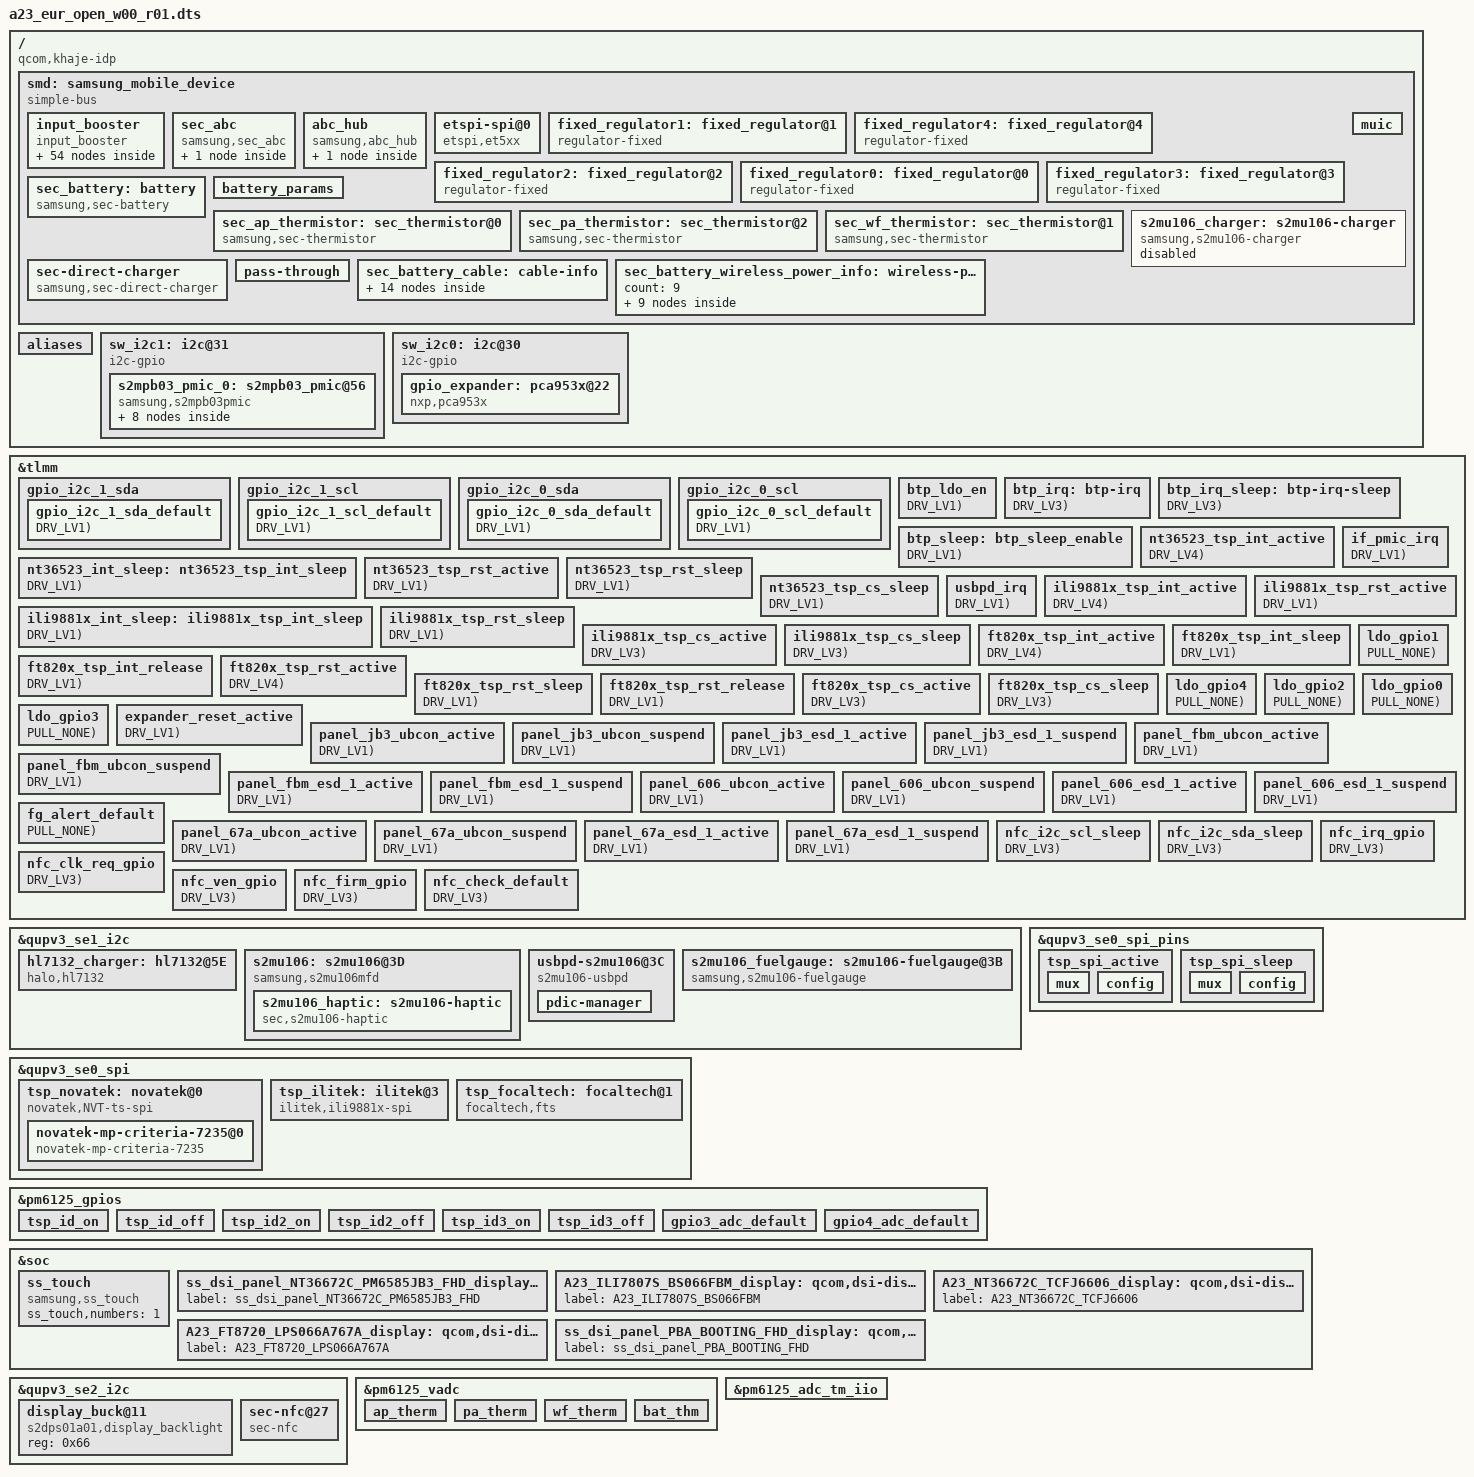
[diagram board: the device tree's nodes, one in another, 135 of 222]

/*
 * Copyright (c) 2018 Samsung Electronics Co., Ltd.
 *              http://www.samsung.com
 *
 * This program is free software; you can redistribute it and/or modify
 * it under the terms of the GNU General Public License version 2 as
 * published by the Free Software Foundation.
*/

/dts-v1/;
/plugin/;
/ {
	fragment@smd {
		target-path = "/";
		__overlay__ {
			smd: samsung_mobile_device {
				compatible = "simple-bus";
			};
		};
	};
};

/* #include "../../sec_pinctrl_wrapper.dtsi" */      /* From sec_pinctrl_wrapper.py */
#define PIN_AP_FUNC_INPUT		"gpio"
#define PIN_AP_FUNC_OUTPUT		"gpio"
#define PIN_AP_FUNC_OUTPUT_LOW		"gpio"
#define PIN_AP_FUNC_OUTPUT_HIGH		"gpio"
#define PIN_AP_FUNC_INPUT_WAKEUP	"gpio"
#define PIN_AP_FUNC_GCC_GP1		"gcc_gp1"
#define PIN_AP_FUNC_GCC_GP2		"gcc_gp2"
#define PIN_AP_FUNC_GCC_GP3		"gcc_gp3"
#define PIN_AP_FUNC_SIMPLE_GPIO		"gpio"
#define PIN_AP_FUNC_MDP_VSYNC		"mdp_vsync"
#define PIN_AP_FUNC_CAM_MCLK		"cam_mclk"

#define	PIN_AP_FUNC_QUP0	"qup0"
#define	PIN_AP_FUNC_QUP1	"qup1"
#define	PIN_AP_FUNC_QUP2	"qup2"
#define	PIN_AP_FUNC_QUP3	"qup3"
#define	PIN_AP_FUNC_QUP4	"qup4"
#define	PIN_AP_FUNC_QUP5	"qup5"
#define	PIN_AP_FUNC_QUP6	"qup6"
#define	PIN_AP_FUNC_QUP7	"qup7"
#define	PIN_AP_FUNC_QUP8	"qup8"
#define	PIN_AP_FUNC_QUP9	"qup9"
#define	PIN_AP_FUNC_QUP10	"qup10"
#define	PIN_AP_FUNC_QUP11	"qup11"
#define	PIN_AP_FUNC_QUP12	"qup12"
#define	PIN_AP_FUNC_QUP13	"qup13"
#define	PIN_AP_FUNC_QUP14	"qup14"
#define	PIN_AP_FUNC_QUP15	"qup15"
#define	PIN_AP_FUNC_QUP16	"qup16"
#define	PIN_AP_FUNC_QUP17	"qup17"
#define	PIN_AP_FUNC_QUP18	"qup18"
#define	PIN_AP_FUNC_QUP19	"qup19"

#define	PIN_AP_FUNC_QUP00	"qup00"
#define	PIN_AP_FUNC_QUP01	"qup01"
#define	PIN_AP_FUNC_QUP02	"qup02"
#define	PIN_AP_FUNC_QUP03	"qup03"
#define	PIN_AP_FUNC_QUP04	"qup04"

/* No support: Build error */
#define PIN_AP_FUNC_PWM		none

#define PIN_PM_FUNC_INPUT		"normal"
#define PIN_PM_FUNC_OUTPUT		"normal"
#define PIN_PM_FUNC_OUTPUT_HIGH		"normal"
#define PIN_PM_FUNC_OUTPUT_LOW		"normal"
#define PIN_PM_FUNC_INPUT_WAKEUP	"normal"
#define PIN_PM_FUNC_PWM			"func1"

#define PIN_DT_FUNC_INPUT		input-enable
#define PIN_DT_FUNC_INPUT_WAKEUP	input-enable
#define PIN_DT_FUNC_OUTPUT_HIGH		output-high
#define PIN_DT_FUNC_OUTPUT_LOW		output-low
#define PIN_DT_FUNC_GCC_GP1		output-high
#define PIN_DT_FUNC_SIMPLE_GPIO		/delete-property/ DUMMY
#define PIN_DT_FUNC_MDP_VSYNC		/delete-property/ DUMMY

#define PIN_DT_FUNC_QUP0	none
#define PIN_DT_FUNC_QUP1	none
#define PIN_DT_FUNC_QUP2	none
#define PIN_DT_FUNC_QUP3	none
#define PIN_DT_FUNC_QUP4	none
#define PIN_DT_FUNC_QUP5	none
#define PIN_DT_FUNC_QUP6	none
#define PIN_DT_FUNC_QUP7	none
#define PIN_DT_FUNC_QUP8	none
#define PIN_DT_FUNC_QUP9	none
#define PIN_DT_FUNC_QUP10	none
#define PIN_DT_FUNC_QUP11	none
#define PIN_DT_FUNC_QUP12	none
#define PIN_DT_FUNC_QUP13	none
#define PIN_DT_FUNC_QUP14	none
#define PIN_DT_FUNC_QUP15	none
#define PIN_DT_FUNC_QUP16	none
#define PIN_DT_FUNC_QUP17	none
#define PIN_DT_FUNC_QUP18	none
#define PIN_DT_FUNC_QUP19	none

#define PIN_DT_FUNC_QUP00	none
#define PIN_DT_FUNC_QUP01	none
#define PIN_DT_FUNC_QUP02	none
#define PIN_DT_FUNC_QUP03	none
#define PIN_DT_FUNC_QUP04	none

/* Only for PMIC */
#define PIN_DT_FUNC_PWM		drive-push-pull

#define PIN_PULL_NONE	bias-disable
#define PIN_PULL_DOWN	bias-pull-down
#define PIN_PULL_UP	bias-pull-up
#define PIN_PULL_OPEN	bias-high-impedance

/*
 * HDRV value | Typical GPIO
 *   (dec)    |       (mA)
 *     0      |       2
 *     1      |       4
 *     2      |       6
 *     3      |       8
 *     4      |       10
 *     5      |       12
 *     6      |       14
 *     7      |       16
 */

#define PIN_AP_DRV_LV1	2
#define PIN_AP_DRV_LV2	4
#define PIN_AP_DRV_LV3	6
#define PIN_AP_DRV_LV4	8
#define PIN_AP_DRV_LV5	10
#define PIN_AP_DRV_LV6	12
#define PIN_AP_DRV_LV7	14
#define PIN_AP_DRV_LV8	16

/*
 * QCOM PMIC GPIO : Need to check!!
 * NO	| 0
 * LOW	| 1	| 0.15mA @ 1.8V
 * MID	| 2	| 0.6mA @ 1.8V
 * HIGH	| 3	| 0.9mA @ 1.8V
 */

#define PIN_PM_DRV_LV1	0
#define PIN_PM_DRV_LV2	0
#define PIN_PM_DRV_LV3	1
#define PIN_PM_DRV_LV4	1
#define PIN_PM_DRV_LV5	2
#define PIN_PM_DRV_LV6	2
#define PIN_PM_DRV_LV7	3
#define PIN_PM_DRV_LV8	3

#define PIN_EXP_PULL_NONE	bias-disable
#define PIN_EXP_PULL_DOWN	bias-pull-down
#define PIN_EXP_PULL_UP		bias-pull-up

#define PIN_EXP_FUNC_INPUT		"normal"
#define PIN_EXP_FUNC_INPUT_WAKEUP	"normal"
#define PIN_EXP_FUNC_OUTPUT		"normal"
#define PIN_EXP_FUNC_OUTPUT_LOW		"normal"
#define PIN_EXP_FUNC_OUTPUT_HIGH	"normal"
#define PIN_EXP_FUNC_SIMPLE_GPIO	"normal"

#define PIN_EXP_DRV_LV1		0
#define PIN_EXP_DRV_LV2		0
#define PIN_EXP_DRV_LV3		1
#define PIN_EXP_DRV_LV4		1
#define PIN_EXP_DRV_LV5		2
#define PIN_EXP_DRV_LV6		2
#define PIN_EXP_DRV_LV7		3
#define PIN_EXP_DRV_LV8		3

#define PIN_EXPAND(pin) #pin

#define GPIO_KEY_WAKEUP		gpio-key,wakeup
#define GPIO_KEY_NONE		none
#define GPIO_KEY_CAN_DISABLE	linux,can-disable
#define GPIO_KEY_CANNOT_DISABLE	linux,cannot-disable

#define SEC_GPIO(src, type, num)	PIN_EXPAND(gpio##num)
#define SEC_GPIO_REF(src, type, num)	&type num
#define SEC_GPIO_NUM(src, type, num)	num
#define SEC_GPIO_TYPE(src, type, num)	&type
#define SEC_GPIO_PHANDLE_ACTIVE(src, type, num)	SEC_GPIO_PHANDLE(type, num, active)
#define SEC_GPIO_PHANDLE_SLEEP(src, type, num)	SEC_GPIO_PHANDLE(type, num, sleep)
#define SEC_GPIO_PHANDLE(type, num, mode)	type##_##num##_##mode

#define GPIO_CONFIG(src, type, num, func)		GPIO_##src##_CONFIG(type, num, func)
#define GPIO_CONFIG_PUD(src, type, num, func, pull)	GPIO_##src##_CONFIG_PUD(type, num, func, pull)
#define GPIO_CONFIG_PUD_DRV(src, type, num, func, pull, drv)	GPIO_##src##_CONFIG_PUD_DRV(type, num, func, pull, drv)

#define GPIO_AP_CONFIG(_type, _num, _func)		\
	mux {						\
		pins = SEC_GPIO(AP, _type, _num);	\
		function = PIN_AP_ ##_func;		\
	};						\
	config {					\
		pins = SEC_GPIO(AP, _type, _num);	\
		PIN_DT_ ##_func;			\
	}

#define GPIO_AP_CONFIG_PUD(_type, _num, _func, _pull)	\
	mux {						\
		pins = SEC_GPIO(AP, _type, _num);	\
		function = PIN_AP_ ##_func;		\
	};						\
	config {					\
		pins = SEC_GPIO(AP, _type, _num);	\
		PIN_DT_ ##_func;			\
		PIN_ ##_pull;				\
	}

#define GPIO_AP_CONFIG_PUD_DRV(_type, _num, _func, _pull, _drv)	\
	mux {						\
		pins = SEC_GPIO(AP, _type, _num);	\
		function = PIN_AP_ ##_func;		\
	};						\
	config {					\
		pins = SEC_GPIO(AP, _type, _num);	\
		drive-strength = <PIN_AP_ ##_drv>;	\
		PIN_DT_ ##_func;			\
		PIN_ ##_pull;				\
	}

#define GPIO_PM_CONFIG(_type, _num, _func)	\
	pins = SEC_GPIO(PM, _type, _num);	\
	function = PIN_PM_ ##_func;	\
	PIN_DT_ ##_func

#define GPIO_PM_CONFIG_PUD(_type, _num, _func, _pull)	\
	pins = SEC_GPIO(PM, _type, _num);		\
	function = PIN_PM_ ##_func;		\
	PIN_DT_ ##_func;				\
	PIN_ ##_pull

#define GPIO_PM_CONFIG_PUD_DRV(_type, _num, _func, _pull, _drv)	\
	pins = SEC_GPIO(PM, _type, _num);		\
	function = PIN_PM_ ##_func;		\
	qcom,drive-strength = <PIN_PM_ ##_drv>;	\
	PIN_DT_ ##_func;				\
	PIN_ ##_pull

#define GPIO_EXP_CONFIG(_type, _num, _func)	\
	pins = SEC_GPIO(EXP, _type, _num);	\
	function = PIN_EXP_ ##_func;	\
	PIN_DT_ ##_func

#define GPIO_EXP_CONFIG_PUD(_type, _num, _func, _pull)	\
	pins = SEC_GPIO(EXP, _type, _num);		\
	function = PIN_EXP_ ##_func;		\
	PIN_DT_ ##_func;				\
	PIN_ ##_pull

#define GPIO_EXP_CONFIG_PUD_DRV(_type, _num, _func, _pull, _drv)	\
	pins = SEC_GPIO(EXP, _type, _num);		\
	function = PIN_EXP_ ##_func;		\
	drive-strength = <PIN_EXP_ ##_drv>;	\
	PIN_DT_ ##_func;				\
	PIN_ ##_pull

#define SEC_ADC(type, num) <&type num>
#define SEC_ADC_OPT(type, num) ,<&type num>
#define SEC_ADC_NUM(type, num) <num>

#define GPIO_KEY_CONFIG(_code, _gpio, _wakeup, _interval)	\
	label = PIN_EXPAND(_code);				\
	linux,code = <_code>;					\
	gpios = <_gpio 1>;					\
	GPIO_KEY_ ##_wakeup;					\
	debounce-interval = <_interval>

#define SEC_INTERFACE_REF(type, num)	&type num


/* #include "../../common/input_booster_sm6225.dtsi" *//* From input_booster_sm6225.py */
/* Copyright (c) 2019, The Linux Foundation. All rights reserved.
 *
 * This program is free software; you can redistribute it and/or modify
 * it under the terms of the GNU General Public License version 2 and
 * only version 2 as published by the Free Software Foundation.
 *
 * This program is distributed in the hope that it will be useful,
 * but WITHOUT ANY WARRANTY; without even the implied warranty of
 * MERCHANTABILITY or FITNESS FOR A PARTICULAR PURPOSE.  See the
 * GNU General Public License for more details.
 */

&smd {
	input_booster {
		status = "okay";
		compatible = "input_booster";
		resValcount = "2";
		max_resource_count = "4";
		max_cluster_count = "3";
		#address-cells = <1>;
		#size-cells = <0>;

		/* Each Cpu Cluster Start Cpu */
		cpu_cluster_policy = "4,0";

		/* < CPU, DDR, HMP, LPM > */
		ib_release_values = "-1,0,-2,0";

		/* Select Allowed Resource Index Group */
		allowed_resources = "0,1,2,3";

		booster_key@1 {
			input_booster,label = "key";
			input_booster,type = <0>;	/* BOOSTER_DEVICE_KEY */

			/* Time table */
			input_booster,head_time = <500>;
			input_booster,tail_time = <500>;

			/* Resource Table Sequentially identified with index
			 * CPU's ID & Index : 0
			 * DDR's ID & Index : 1
			 * HMP's ID & Index : 2
			 * LPM's ID & Index : 3
			*/

			/* Input Booster Resource Frequency */
			inputbooster,resource {
				compatible = "resource";
				resource@1 {
					resource,label = "CPU";
					resource,value = <1344000 0>;
				};

				resource@2 {
					resource,label = "DDR";
					resource,value = <0 0>;
				};

				resource@3 {
					resource,label = "HMP";
					resource,value = <2 0>;
				};

				resource@4 {
					resource,label = "LPM";
					resource,value = <0 0>;
				};
			};
		};
		booster_key@2 {
			input_booster,label = "touchkey";
			input_booster,type = <1>;	/* BOOSTER_DEVICE_TOUCHKEY */

			/* Time table */
			input_booster,head_time = <0>;
			input_booster,tail_time = <500>;

			/* Input Booster Resource Frequency */
			inputbooster,resource {
				compatible = "resource";
				resource@1 {
					resource,label = "CPU";
					resource,value = <1344000 0>;
				};

				resource@2 {
					resource,label = "DDR";
					resource,value = <0 0>;
				};

				resource@3 {
					resource,label = "HMP";
					resource,value = <2 0>;
				};

				resource@4 {
					resource,label = "LPM";
					resource,value = <0 0>;
				};
			};
		};
		booster_key@3 {
			input_booster,label = "touch";
			input_booster,type = <2>;	/* BOOSTER_DEVICE_TOUCH */

			/* Time table */
			input_booster,head_time = <200>;
			input_booster,tail_time = <300>;

			/* Input Booster Resource Frequency */
			inputbooster,resource {
				compatible = "resource";
				resource@1 {
					resource,label = "CPU";
					resource,value = <1344000 1036800>;
				};

				resource@2 {
					resource,label = "DDR";
					resource,value = <1017 0>;
				};

				resource@3 {
					resource,label = "HMP";
					resource,value = <2 2>;
				};

				resource@4 {
					resource,label = "LPM";
					resource,value = <5 5>;
				};
			};
		};
		booster_key@4 {
			input_booster,label = "multitouch";
			input_booster,type = <3>;	/* BOOSTER_DEVICE_MULTITOUCH */

			/* Time table */
			input_booster,head_time = <200>;
			input_booster,tail_time = <800>;

			/* Input Booster Resource Frequency */
			inputbooster,resource {
				compatible = "resource";
				resource@1 {
					resource,label = "CPU";
					resource,value = <1766400 1344000>;
				};

				resource@2 {
					resource,label = "DDR";
					resource,value = <0 0>;
				};

				resource@3 {
					resource,label = "HMP";
					resource,value = <2 2>;
				};

				resource@4 {
					resource,label = "LPM";
					resource,value = <0 0>;
				};
			};
		};
		booster_key@5 {
			input_booster,label = "keyboard";
			input_booster,type = <4>;	/* BOOSTER_DEVICE_KEYBOARD */

			/* Time table */
			input_booster,head_time = <130>;
			input_booster,tail_time = <0>;

			/* Input Booster Resource Frequency */
			inputbooster,resource {
				compatible = "resource";
				resource@1 {
					resource,label = "CPU";
					resource,value = <1344000 1344000>;
				};

				resource@2 {
					resource,label = "DDR";
					resource,value = <0 0>;
				};

				resource@3 {
					resource,label = "HMP";
					resource,value = <2 2>;
				};

				resource@4 {
					resource,label = "LPM";
					resource,value = <0 0>;
				};
			};
		};
		booster_key@6 {
			input_booster,label = "mouse";
			input_booster,type = <5>;	/* BOOSTER_DEVICE_MOUSE */

			/* Time table */
			input_booster,head_time = <200>;
			input_booster,tail_time = <300>;

			/* Input Booster Resource Frequency */
			inputbooster,resource {
				compatible = "resource";
				resource@1 {
					resource,label = "CPU";
					resource,value = <1344000 489600>;
				};

				resource@2 {
					resource,label = "DDR";
					resource,value = <0 0>;
				};

				resource@3 {
					resource,label = "HMP";
					resource,value = <2 0>;
				};

				resource@4 {
					resource,label = "LPM";
					resource,value = <0 0>;
				};
			};
		};
		booster_key@7 {
			input_booster,label = "mouse_wheel";
			input_booster,type = <6>;	/* BOOSTER_DEVICE_MOUSE */

			/* Time table */
			input_booster,head_time = <200>;
			input_booster,tail_time = <0>;

			/* Input Booster Resource Frequency */
			inputbooster,resource {
				compatible = "resource";
				resource@1 {
					resource,label = "CPU";
					resource,value = <1344000 0>;
				};

				resource@2 {
					resource,label = "DDR";
					resource,value = <0 0>;
				};

				resource@3 {
					resource,label = "HMP";
					resource,value = <2 0>;
				};

				resource@4 {
					resource,label = "LPM";
					resource,value = <0 0>;
				};
			};
		};
		booster_key@8 {
			input_booster,label = "pen_hover";
			input_booster,type = <7>;	/* BOOSTER_DEVICE_MOUSE */

			/* Time table */
			input_booster,head_time = <200>;
			input_booster,tail_time = <300>;

			/* Input Booster Resource Frequency */
			inputbooster,resource {
				compatible = "resource";
				resource@1 {
					resource,label = "CPU";
					resource,value = <1344000 489600>;
				};

				resource@2 {
					resource,label = "DDR";
					resource,value = <0 0>;
				};

				resource@3 {
					resource,label = "HMP";
					resource,value = <2 0>;
				};

				resource@4 {
					resource,label = "LPM";
					resource,value = <0 0>;
				};
			};
		};
		booster_key@9 {
			input_booster,label = "pen";
			input_booster,type = <8>;	/* BOOSTER_DEVICE_MOUSE */

			/* Time table */
			input_booster,head_time = <200>;
			input_booster,tail_time = <600>;

			/* Input Booster Resource Frequency */
			inputbooster,resource {
				compatible = "resource";
				resource@1 {
					resource,label = "CPU";
					resource,value = <1766400 1056000>;
				};

				resource@2 {
					resource,label = "DDR";
					resource,value = <0 0>;
				};

				resource@3 {
					resource,label = "HMP";
					resource,value = <2 2>;
				};

				resource@4 {
					resource,label = "LPM";
					resource,value = <5 5>;
				};
			};
		};
		/* If you need to add new key type, add it this position */
	};
};
/* #include "../../abc_spec_manager_type1.dtsi" */   /* From abc_spec_manager_type1.py */
&smd {
	sec_abc {
		compatible = "samsung,sec_abc";
		status = "okay";
		abc_spec_type1 {
			module_list = "gpu", "gpu_qc", "gpu_qc", "camera", "camera", "vib";
			name_list = "gpu_fault", "gpu_fault", "gpu_page_fault", "mipi_overflow", "i2c_fail", "int_gnd_short";
			threshold_cnt = <20>, <2>, <20>, <1>, <1>, <25>;
			threshold_time = <1200>, <1200>, <1200>, <0>, <0>, <5>;
		};
	};
};

/* #include "../../ap_qcom_sm6225.dtsi" */           /* From ap_qcom_sm6225.py */
/* Copyright (c) 2019, The Linux Foundation. All rights reserved.
 *
 * This program is free software; you can redistribute it and/or modify
 * it under the terms of the GNU General Public License version 2 and
 * only version 2 as published by the Free Software Foundation.
 *
 * This program is distributed in the hope that it will be useful,
 * but WITHOUT ANY WARRANTY; without even the implied warranty of
 * MERCHANTABILITY or FITNESS FOR A PARTICULAR PURPOSE.  See the
 * GNU General Public License for more details.
 */

#include <dt-bindings/interrupt-controller/arm-gic.h>
#include "../../../vendor/qcom/khaje-idp-nopmi.dtsi"


/* #include "../../abc_common.dtsi" */               /* From abc_common.py */
&smd {
	abc_hub {
		compatible = "samsung,abc_hub";
		status = "okay";
		bootc {
			bootc,time_spec_user = <100000>; /* user binary user build */
			bootc,time_spec_eng = <150000>; /* user binary eng build */
			bootc,time_spec_fac = <100000>; /* factory binary */
		};
	};
};

/* #include "../../i2c-gpio-1.dtsi" */               /* From i2c-gpio.py */
&tlmm {
       gpio_i2c_1_sda {
               gpio_i2c_1_sda_default: gpio_i2c_1_sda_default {
                       GPIO_CONFIG_PUD_DRV(AP,tlmm,83, FUNC_INPUT, PULL_NONE, DRV_LV1);
               };
       };
};

&tlmm {
       gpio_i2c_1_scl {
               gpio_i2c_1_scl_default: gpio_i2c_1_scl_default {
                       GPIO_CONFIG_PUD_DRV(AP,tlmm,84, FUNC_INPUT, PULL_NONE, DRV_LV1);
               };
       };
};

/ {
	fragment@model {
		target-path = "/";
	        __overlay__ {
			aliases {
				  i2c31 = "/i2c@31";
			};
			/* Software I2C */
			sw_i2c1: i2c@31 {
				cell-index = <31>;
				compatible = "i2c-gpio";
				gpios = <
					SEC_GPIO_REF(AP,tlmm,83) 0 /* SDA */
					SEC_GPIO_REF(AP,tlmm,84) 0 /* SCL */
					>;
				#i2c-gpio,delay-us = <2>;
				#address-cells = <1>;
				#size-cells = <0>;

				pinctrl-names = "default";
				pinctrl-0 = <
					&gpio_i2c_1_sda_default
					&gpio_i2c_1_scl_default
					>;

				status = "disabled";
			};
		};
	};
};


/* #include "../../i2c-gpio.dtsi" */                 /* From i2c-gpio.py */
&tlmm {
       gpio_i2c_0_sda {
               gpio_i2c_0_sda_default: gpio_i2c_0_sda_default {
                       GPIO_CONFIG_PUD_DRV(AP,tlmm,92, FUNC_INPUT, PULL_NONE, DRV_LV1);
               };
       };
};

&tlmm {
       gpio_i2c_0_scl {
               gpio_i2c_0_scl_default: gpio_i2c_0_scl_default {
                       GPIO_CONFIG_PUD_DRV(AP,tlmm,93, FUNC_INPUT, PULL_NONE, DRV_LV1);
               };
       };
};

/ {
	fragment@model {
		target-path = "/";
	        __overlay__ {
			aliases {
				  i2c30 = "/i2c@30";
			};
			/* Software I2C */
			sw_i2c0: i2c@30 {
				cell-index = <30>;
				compatible = "i2c-gpio";
				gpios = <
					SEC_GPIO_REF(AP,tlmm,92) 0 /* SDA */
					SEC_GPIO_REF(AP,tlmm,93) 0 /* SCL */
					>;
				#i2c-gpio,delay-us = <2>;
				#address-cells = <1>;
				#size-cells = <0>;

				pinctrl-names = "default";
				pinctrl-0 = <
					&gpio_i2c_0_sda_default
					&gpio_i2c_0_scl_default
					>;

				status = "disabled";
			};
		};
	};
};


/* #include "../../hl7132_charger.dtsi" */           /* From hl7132_charger.py */
&qupv3_se1_i2c {
	status = "okay";

	hl7132_charger: hl7132@5E {
		compatible = "halo,hl7132";
		reg = <0x5E>;

		/* All properties can be changed by customer ! */
		/* VBAT Regualtion Voltage ::  4.34  */
		hl7132,vbat-reg = <4340000>;
		/* Input Current Limit : 2A */
		hl7132,input-current-limit = <2000000>;
		/* Topoff Current :: 500mA */
		hl7132,topoff-current = <500000>;
		/* ts protection Enabled */
		//hl7132,ts-prot-en;
		/* All auto recovery Disabled */
		//hl7132,all-auto-recovery;
		/* Enable Manual mode, Set 8-samples, Enable ADC-Read */
		hl7132,adc-ctrl0 = <0x85>;
		/* Set ts0 to SSMC requirement*/
		hl7132,ts0-th = <0x0048>;
		/* Set ts1 to SSMC requirement*/
		hl7132,ts1-th = <0x03AC>;
		/* watchdog timer setting : 16S */
		hl7132,wd-tmr = <0x3>;
		/* WDT enabled */
		//hl7132,wd-dis;
		hl7132,fsw-set = <0x06>; //1100khz default setting
	};
};

/* /home/dpi/qb5_8815/workspace/P4_1716/android/kernel/kmodule/battery/suwon/charger/hl7132/hl7132_charger.a23.dtsi */

&hl7132_charger {
	/* ts protection Enabled */
	hl7132,ts-prot-en;
};

/* #include "../../fingerprint_et5xx.dtsi" */        /* From fingerprint_et5xx.py */
/*
 * Copyright (c) 2021, The Linux Foundation. All rights reserved.
 *
 * This program is free software; you can redistribute it and/or modify
 * it under the terms of the GNU General Public License version 2 and
 * only version 2 as published by the Free Software Foundation.
 *
 * This program is distributed in the hope that it will be useful,
 * but WITHOUT ANY WARRANTY; without even the implied warranty of
 * MERCHANTABILITY or FITNESS FOR A PARTICULAR PURPOSE.  See the
 * GNU General Public License for more details.
 */

&tlmm {
	btp_ldo_en: btp_ldo_en {
		GPIO_CONFIG_PUD_DRV(AP,tlmm,96, FUNC_OUTPUT_LOW, PULL_NONE, DRV_LV1);
	};
};

&tlmm {
	btp_irq: btp-irq {
		GPIO_CONFIG_PUD_DRV(AP,tlmm,102, FUNC_INPUT_WAKEUP, PULL_NONE, DRV_LV3);
	};
	btp_irq_sleep: btp-irq-sleep {
		GPIO_CONFIG_PUD_DRV(AP,tlmm,102, FUNC_INPUT, PULL_DOWN, DRV_LV3);
	};
};

&tlmm {
	btp_sleep: btp_sleep_enable {
		GPIO_CONFIG_PUD_DRV(AP,tlmm,103, FUNC_OUTPUT_LOW, PULL_DOWN, DRV_LV1);
	};
};


&smd {
	#address-cells = <1>;
	#size-cells = <0>;

	etspi-spi@0 {
		compatible = "etspi,et5xx";
		reg = <0x00>;
		spi-max-frequency = <12500000>;

		pinctrl-names = "default", "pins_poweron", "pins_poweroff"
						, "pins_poweron_tz", "pins_poweroff_tz";
		pinctrl-0 = <&btp_sleep &btp_irq &btp_ldo_en>;
		pinctrl-1 = <&btp_irq>;
		pinctrl-2 = <&btp_irq_sleep>;
		pinctrl-3 = <&btp_irq>;
		pinctrl-4 = <&btp_irq_sleep>;
		gpio-controller;
		#gpio-cells = <2>;
		etspi-ldoPin = <SEC_GPIO_REF(AP,tlmm,96) 0>;
		etspi-sleepPin = <SEC_GPIO_REF(AP,tlmm,103) 0>;
		etspi-drdyPin = <SEC_GPIO_REF(AP,tlmm,102) 0>;
		etspi-chipid = "ET528";
		etspi-orient = <2>;
	};
};

/* #include "../../input_nt36523_spi.dtsi" */        /* From input_nt36523_spi.py */
/*
 * SAMSUNG EXYNOS850 board common device tree source
 *
 * Copyright (c) 2019 Samsung Electronics Co., Ltd.
 *		http://www.samsung.com
 *
 * This program is free software; you can redistribute it and/or modify
 * it under the terms of the GNU General Public License version 2 as
 * published by the Free Software Foundation.
 */

&tlmm {
	nt36523_tsp_int_active: nt36523_tsp_int_active {
		GPIO_CONFIG_PUD_DRV(AP,tlmm,34, FUNC_INPUT_WAKEUP, PULL_NONE, DRV_LV4);
	};

	nt36523_int_sleep: nt36523_tsp_int_sleep {
		GPIO_CONFIG_PUD_DRV(AP,tlmm,34, FUNC_INPUT, PULL_DOWN, DRV_LV1);
	};
};

&qupv3_se0_spi {
	status = "ok";
	num-cs = <1>;

	/* Novatek device tree node */
	tsp_novatek: novatek@0 {
		spi-max-frequency = <9600000>;
		compatible = "novatek,NVT-ts-spi";
		reg = <0>;
		status = "okay";

		pinctrl-names = "default", "on_state", "off_state";
		pinctrl-0 = <&nt36523_tsp_int_active>;
		pinctrl-1 = <&nt36523_tsp_int_active>;
		pinctrl-2 = <&nt36523_int_sleep &nt36523_tsp_rst_sleep>;

		novatek,irq-gpio = <SEC_GPIO_REF(AP,tlmm,34) 0x2002>;
		novatek,cs-gpio = <SEC_GPIO_REF(AP,tlmm,3) 0>;
	};
};

/* /home/dpi/qb5_8815/workspace/P4_1716/android/kernel/kmodule/input/touchscreen/novatek/nt36523_spi/dts/input-qc-tsp-nt36523-spi.a23.dtsi */
/*
 * SAMSUNG EXYNOS850 board common device tree source
 *
 * Copyright (c) 2019 Samsung Electronics Co., Ltd.
 *		http://www.samsung.com
 *
 * This program is free software; you can redistribute it and/or modify
 * it under the terms of the GNU General Public License version 2 as
 * published by the Free Software Foundation.
 */
&pm6125_gpios {
	tsp_id_on: tsp_id_on {
		pins = "gpio2";
		function = "normal";
		input-enable;
		bias-disable;
	};
	tsp_id_off: tsp_id_off {
		pins = "gpio2";
		function = "normal";
		input-enable;
		bias-disable;
	};
	tsp_id2_on: tsp_id2_on {
		pins = "gpio8";
		function = "normal";
		power-source = <1>;
		input-enable;
		bias-disable;
	};
	tsp_id2_off: tsp_id2_off {
		pins = "gpio8";
		function = "normal";
		power-source = <1>;
		input-enable;
		bias-disable;
	};
	tsp_id3_on: tsp_id3_on {
		pins = "gpio9";
		function = "normal";
		power-source = <1>;
		input-enable;
		bias-disable;
	};
	tsp_id3_off: tsp_id3_off {
		pins = "gpio9";
		function = "normal";
		power-source = <1>;
		input-enable;
		bias-disable;
	};
};

&qupv3_se0_spi_pins {
	tsp_spi_active: tsp_spi_active {
		mux {
			pins = "gpio0", "gpio1",
				"gpio2";
			function = "qup0";
		};

		config {
			pins = "gpio0", "gpio1",
				"gpio2";
			drive-strength = <6>;
			bias-disable;
		};
	};
	tsp_spi_sleep: tsp_spi_sleep {
		mux {
			pins = "gpio0", "gpio1",
				"gpio2";
			function = "gpio";
		};

		config {
			pins = "gpio0", "gpio1",
				"gpio2";
			drive-strength = <6>;
			bias-pull-down;
		};
	};
};


&tlmm {
	nt36523_tsp_rst_active: nt36523_tsp_rst_active {
		GPIO_CONFIG_PUD_DRV(AP,tlmm,81, FUNC_INPUT, PULL_DOWN, DRV_LV1);
	};

	nt36523_tsp_rst_sleep: nt36523_tsp_rst_sleep {
		GPIO_CONFIG_PUD_DRV(AP,tlmm,81, FUNC_INPUT, PULL_DOWN, DRV_LV1);
	};
};

&tlmm {
	nt36523_tsp_cs_sleep: nt36523_tsp_cs_sleep {
		GPIO_CONFIG_PUD_DRV(AP,tlmm,3, FUNC_INPUT, PULL_DOWN, DRV_LV1);
	};
};

&qupv3_se0_spi {
	pinctrl-0 = <&tsp_id_on &tsp_id2_on &tsp_id3_on &tsp_spi_active>;
	pinctrl-1 = <&tsp_id_off &tsp_id2_off &tsp_id3_off &tsp_spi_sleep>;
	num-cs = <3>;
};

&tsp_novatek {
	pinctrl-0 = <&nt36523_tsp_int_active &nt36523_tsp_rst_active &nt36523_tsp_cs_sleep>;
	pinctrl-2 = <&nt36523_int_sleep &nt36523_tsp_rst_sleep &nt36523_tsp_cs_sleep>;

	novatek,resolution = <1080 2408>;
	novatek,enable_settings_aot;
	novatek,support_ear_detect_mode;
	novatek,prox_lp_scan_enabled;
	novatek,enable_sysinput_enabled;

	novatek,lcdid1-gpio = <&pm6125_gpios 2 0x0>;
	novatek,lcdid2-gpio = <&pm6125_gpios 8 0x0>;
	novatek,lcdid3-gpio = <&pm6125_gpios 9 0x0>;
	novatek,lcdid = <0 3>;	// CSO Sharp
	novatek,lcdtype = <0x4bf240 0 0 0x4b1260>;

	novatek,fw_name = "tsp_novatek/nt36672_a23_csot.bin", "", "", "tsp_novatek/nt36672_a23_sharp.bin";
	novatek,fw_name_mp = "tsp_novatek/nt36672_a23_csot_mp.bin", "", "", "tsp_novatek/nt36672_a23_sharp_mp.bin";

	novatek,name_lcd_rst = "lcd_rst";
	novatek,name_lcd_vddi = "lcd_vddi";
	novatek,name_lcd_bl_en = "lcd_bl_en";
	novatek,name_lcd_vsp = "lcd_vsp";
	novatek,name_lcd_vsn = "lcd_vsn";

	/* 672A, 525B, 675, 526, 672C */
	novatek,swrst-n8-addr = <0x03F0FE>;
	novatek,spi-rd-fast-addr = <0x03F310>;

	/* MP */
	novatek,mp-support-dt;

	/* nt36672_m33x_csot.bin */
	novatek-mp-criteria-7235@0 {
		#address-cells = <1>;
		#size-cells = <0>;
		compatible = "novatek-mp-criteria-7235";

		/* sec cmd test config */
		open_test_spec = <(-511) 5120>;
		short_test_spec = <10000 14008>;
		diff_test_frame = <50>;
		fdm_x_num = <2>;
	};
};

&soc {
	ss_touch {
		compatible = "samsung,ss_touch";
		ss_touch,numbers = <1>;
	};
};


/* #include "../../s2mu106.dtsi" */                  /* From s2mu106.py */
&tlmm {
	if_pmic_irq: if_pmic_irq {
		GPIO_CONFIG_PUD_DRV(AP,tlmm,25, FUNC_INPUT_WAKEUP, PULL_NONE, DRV_LV1);
	};
};

&tlmm {
	usbpd_irq: usbpd_irq {
		GPIO_CONFIG_PUD_DRV(AP,tlmm,80, FUNC_INPUT_WAKEUP, PULL_NONE, DRV_LV1);
	};
};



&qupv3_se1_i2c {
	#address-cells = <1>;
	#size-cells = <0>;
	status = "okay";
	clock-frequency = <400000>;
	samsung,i2c-max-bus-freq = <400000>;

	s2mu106: s2mu106@3D {
		status = "okay";
		compatible = "samsung,s2mu106mfd";
		reg = <0x3D>;
		pinctrl-names = "default";
		pinctrl-0 = <&if_pmic_irq>;
		s2mu106,irq-gpio = <SEC_GPIO_REF(AP,tlmm,25) 1>;
		s2mu106,wakeup;
	};
};

&qupv3_se1_i2c {
	#address-cells = <1>;
	#size-cells = <0>;
	status = "okay";
	clock-frequency = <400000>;
	samsung,i2c-max-bus-freq = <400000>;

	usbpd-s2mu106@3C {
		status = "okay";
		compatible = "s2mu106-usbpd";
		reg = <0x3C>;
		pinctrl-names = "default";
		pinctrl-0 = <&usbpd_irq 
						>;
		usbpd,usbpd_int = <SEC_GPIO_REF(AP,tlmm,80) 0>;

		pdic-manager {
			/* sink */
			pdic,max_power = <5000>;
			pdic_op_power = <2500>;
			pdic_max_voltage = <6000>;
			pdic_max_current = <2000>;
			pdic,min_current = <500>;

			pdic,giveback = <0>;
			pdic,usb_com_capable = <1>;
			pdic,no_usb_suspend = <1>;

			/* source */
			source,max_voltage = <5000>;
			source,min_voltage = <4000>;
			source,max_power = <2500>;

			/* sink cap */
			sink,capable_max_voltage = <5000>;
		};
	};
};

/* #include "../../input_ili9881x.dtsi" */           /* From input_ili9881x.py */
/*
 * SAMSUNG EXYNOS850 board common device tree source
 *
 * Copyright (c) 2019 Samsung Electronics Co., Ltd.
 *		http://www.samsung.com
 *
 * This program is free software; you can redistribute it and/or modify
 * it under the terms of the GNU General Public License version 2 as
 * published by the Free Software Foundation.
 */

&tlmm {
	ili9881x_tsp_int_active: ili9881x_tsp_int_active {
		GPIO_CONFIG_PUD_DRV(AP,tlmm,34, FUNC_INPUT_WAKEUP, PULL_NONE, DRV_LV4);
	};

	ili9881x_int_sleep: ili9881x_tsp_int_sleep {
		GPIO_CONFIG_PUD_DRV(AP,tlmm,34, FUNC_INPUT, PULL_DOWN, DRV_LV1);
	};
};

&tlmm {
	ili9881x_tsp_rst_active: ili9881x_tsp_rst_active {
		GPIO_CONFIG_PUD_DRV(AP,tlmm,81, FUNC_INPUT, PULL_DOWN, DRV_LV1);
	};

	ili9881x_tsp_rst_sleep: ili9881x_tsp_rst_sleep {
		GPIO_CONFIG_PUD_DRV(AP,tlmm,81, FUNC_INPUT, PULL_DOWN, DRV_LV1);
	};
};

&tlmm {
	ili9881x_tsp_cs_active: ili9881x_tsp_cs_active {
		GPIO_CONFIG_PUD_DRV(AP,tlmm,3, FUNC_OUTPUT_HIGH, PULL_UP, DRV_LV3);
	};

	ili9881x_tsp_cs_sleep: ili9881x_tsp_cs_sleep {
		GPIO_CONFIG_PUD_DRV(AP,tlmm,3, FUNC_OUTPUT_LOW, PULL_DOWN, DRV_LV3);
	};
};

&qupv3_se0_spi {
	status = "ok";
	num-cs = <1>;

	tsp_ilitek: ilitek@3 {
		spi-max-frequency = <9600000>;
		compatible = "ilitek,ili9881x-spi";
		reg = <3>;
		status = "okay";

		pinctrl-names = "default", "on_state", "off_state";
		pinctrl-0 = <&ili9881x_tsp_int_active &ili9881x_tsp_rst_active>;
		pinctrl-1 = <&ili9881x_tsp_int_active &ili9881x_tsp_rst_active &ili9881x_tsp_cs_active>;
		pinctrl-2 = <&ili9881x_int_sleep &ili9881x_tsp_rst_sleep &ili9881x_tsp_cs_sleep>;

		ilitek,reset-gpio = <SEC_GPIO_REF(AP,tlmm,81) 0x00>;
		ilitek,irq-gpio = <SEC_GPIO_REF(AP,tlmm,34) 0x2002>;
		ilitek,cs-gpio = <SEC_GPIO_REF(AP,tlmm,3) 0>;

		ilitek,irq-on-state = <0>;
		ilitek,spi-mode = <0>;
		ilitek,byte-delay-us = <0>;
		ilitek,block-delay-us = <0>;
		ilitek,ubl-max-freq = <5000000>;
		ilitek,ubl-byte-delay-us = <20>;
		/* power capacitor discharging delay */
		ilitek,poweroff-discharging-us = <0>;
		
		ilitek,enable_sysinput_enabled;
	};
};

/* /home/dpi/qb5_8815/workspace/P4_1716/android/kernel/kmodule/input/touchscreen/ilitek/ili9881x/dts/input-qc-tsp-ili9881x.a23.dtsi */
/*
 * SAMSUNG EXYNOS850 board common device tree source
 *
 * Copyright (c) 2019 Samsung Electronics Co., Ltd.
 *		http://www.samsung.com
 *
 * This program is free software; you can redistribute it and/or modify
 * it under the terms of the GNU General Public License version 2 as
 * published by the Free Software Foundation.
 */

&qupv3_se0_spi {
	num-cs = <3>;
};

&tsp_ilitek {
	ilitek,lcdid1-gpio = <&pm6125_gpios 2 0x0>;
	ilitek,lcdid2-gpio = <&pm6125_gpios 8 0x0>;
	ilitek,lcdid3-gpio = <&pm6125_gpios 9 0x0>;
	ilitek,lcdid = <0 5>;
	ilitek,lcdtype = <0 0 0 0 0 0x4b6250>;
	ilitek,fw_name = "", "", "", "", "", "tsp_ilitek/ili7807_a23.hex";

	ilitek,lcd_rst = "lcd_rst";
	ilitek,lcd_bl_en = "lcd_bl_en";
	ilitek,lcd_vddi = "lcd_vddi";
	ilitek,lcd_vsp = "lcd_vsp";
	ilitek,lcd_vsn = "lcd_vsn";

	ilitek,poweroff-discharging-us = <2000>;

	ilitek,area-size = <48 81 30>;
	ilitek,enable_settings_aot;
	ilitek,support_ear_detect_mode;
	ilitek,prox_lp_scan_enabled;
	ilitek,support_spay_gesture_mode;
};

&soc {
	ss_touch {
		compatible = "samsung,ss_touch";
		ss_touch,numbers = <1>;
	};
};

/* #include "../../pmic_PM6225.dtsi" */              /* From pmic_PM6225.py */
























/* #include "../../input_ft8720.dtsi" */             /* From input_ft8720.py */
&tlmm {
	ft820x_tsp_int_active: ft820x_tsp_int_active {
		GPIO_CONFIG_PUD_DRV(AP,tlmm,34, FUNC_INPUT_WAKEUP, PULL_UP, DRV_LV4);
	};

	ft820x_tsp_int_sleep: ft820x_tsp_int_sleep {
		GPIO_CONFIG_PUD_DRV(AP,tlmm,34, FUNC_INPUT, PULL_DOWN, DRV_LV1);
	};

	ft820x_tsp_int_release: ft820x_tsp_int_release {
		GPIO_CONFIG_PUD_DRV(AP,tlmm,34, FUNC_INPUT, PULL_NONE, DRV_LV1);
	};
};

&tlmm {
	ft820x_tsp_rst_active: ft820x_tsp_rst_active {
		GPIO_CONFIG_PUD_DRV(AP,tlmm,81, FUNC_INPUT, PULL_UP, DRV_LV4);
	};

	ft820x_tsp_rst_sleep: ft820x_tsp_rst_sleep {
		GPIO_CONFIG_PUD_DRV(AP,tlmm,81, FUNC_INPUT, PULL_DOWN, DRV_LV1);
	};

	ft820x_tsp_rst_release: ft820x_tsp_rst_release {
		GPIO_CONFIG_PUD_DRV(AP,tlmm,81, FUNC_INPUT, PULL_NONE, DRV_LV1);
	};
};

&qupv3_se0_spi {
	status = "okay";
	num-cs = <1>;
	cs-gpios = <SEC_GPIO_REF(AP,tlmm,3) 0>;

	tsp_focaltech: focaltech@1 {
		spi-max-frequency = <6000000>;
		compatible = "focaltech,fts";
		reg = <1>;
		status = "okay";
		pinctrl-names = "pmx_ts_active","pmx_ts_suspend","pmx_ts_release";
		pinctrl-0 = <&ft820x_tsp_int_active &ft820x_tsp_rst_active>;
		pinctrl-1 = <&ft820x_tsp_int_sleep &ft820x_tsp_rst_sleep>;
		pinctrl-2 = <&ft820x_tsp_int_release &ft820x_tsp_rst_release>;
		focaltech,irq-gpio = <SEC_GPIO_REF(AP,tlmm,34) 0x02>;
		focaltech,reset-gpio = <SEC_GPIO_REF(AP,tlmm,81) 0x01>;
		focaltech,panel_buck_en = "panel_buck_en";
		focaltech,panel_buck_en2 = "panel_buck_en2";
		focaltech,panel_ldo_en = "panel_ldo_en";
		focaltech,panel_reset ="panel_reset";
		focaltech,max-touch-number = <10>;
		focaltech,display-coords = <0 0 1600 2560>;
		sec,firmware_name = "tsp_focaltech/ft8203_a23.bin";
		enable_sysinput_enabled;
		support_dex;
	};
};


/* /home/dpi/qb5_8815/workspace/P4_1716/android/kernel/kmodule/input/touchscreen/focaltech/ft8720/dts/input-qc-tsp-ft8720.a23.dtsi */
&tlmm {
	ft820x_tsp_cs_active: ft820x_tsp_cs_active {
		GPIO_CONFIG_PUD_DRV(AP,tlmm,3, FUNC_OUTPUT_HIGH, PULL_NONE, DRV_LV3);
	};
	ft820x_tsp_cs_sleep: ft820x_tsp_cs_sleep {
		GPIO_CONFIG_PUD_DRV(AP,tlmm,3, FUNC_OUTPUT_LOW, PULL_DOWN, DRV_LV3);
	};
};

&qupv3_se0_spi {
	num-cs = <2>;
	cs-gpios = <SEC_GPIO_REF(AP,tlmm,3) 0>, <SEC_GPIO_REF(AP,tlmm,3) 0>;
};

&tsp_focaltech {
	pinctrl-0 = <&ft820x_tsp_int_active &ft820x_tsp_rst_active &ft820x_tsp_cs_active>;
	pinctrl-1 = <&ft820x_tsp_int_sleep &ft820x_tsp_rst_sleep &ft820x_tsp_cs_sleep>;

	focaltech,display-coords = <0 0 1080 2408>;

	sec,lcdid1-gpio = <&pm6125_gpios 2 0x0>;
	sec,lcdid2-gpio = <&pm6125_gpios 8 0x0>;
	sec,lcdid3-gpio = <&pm6125_gpios 9 0x0>;
	sec,lcdid = <6>;
	sec,lcdtype = <0 0 0 0 0 0 0x4b1270>;

	sec,firmware_name = "", "", "", "", "", "", "tsp_focaltech/ft8720_a23.bin";
	focaltech,ramtest_name = "tsp_focaltech/ft8720_a23_ramtest.bin";

	sec,name_lcd_rst = "lcd_rst";
	sec,name_lcd_vddi = "lcd_vddi";
	sec,name_lcd_bl_en = "lcd_bl_en";
	sec,name_lcd_vsp = "lcd_vsp";
	sec,name_lcd_vsn = "lcd_vsn";

	enable_settings_aot;
	prox_lp_scan_enabled;
	scan_off_when_cover_closed;
	enable_vbus_notifier;
};

&soc {
	ss_touch {
		compatible = "samsung,ss_touch";
		ss_touch,numbers = <1>;
	};
};

/* #include "../../regulator-fixe-1.dtsi" */         /* From regulator-fixed.py */
/* 
 * This pinctrl code is only for PULL state change.
 * IN-OUT setting is set to OUTPUT at fixed-regulator probe.
 */

&tlmm {
        ldo_gpio1: ldo_gpio1 {
                GPIO_CONFIG_PUD(AP,tlmm,48, FUNC_OUTPUT_HIGH, PULL_NONE);
        };
};

&smd {
	fixed_regulator1: fixed_regulator@1 {
		compatible = "regulator-fixed";
		regulator-name = "fixed_regulator1";
		gpio = <SEC_GPIO_REF(AP,tlmm,48) 0>;
		pinctrl-names = "default";
		pinctrl-0 = <&ldo_gpio1>;
		enable-active-high;regulator-boot-on;
	};
};


/* #include "../../regulator-fixe-4.dtsi" */         /* From regulator-fixed.py */
/* 
 * This pinctrl code is only for PULL state change.
 * IN-OUT setting is set to OUTPUT at fixed-regulator probe.
 */

&tlmm {
        ldo_gpio4: ldo_gpio4 {
                GPIO_CONFIG_PUD(AP,tlmm,31, FUNC_OUTPUT_HIGH, PULL_NONE);
        };
};

&smd {
	fixed_regulator4: fixed_regulator@4 {
		compatible = "regulator-fixed";
		regulator-name = "fixed_regulator4";
		gpio = <SEC_GPIO_REF(AP,tlmm,31) 0>;
		pinctrl-names = "default";
		pinctrl-0 = <&ldo_gpio4>;
		enable-active-high;
	};
};


/* #include "../../regulator-fixe-2.dtsi" */         /* From regulator-fixed.py */
/* 
 * This pinctrl code is only for PULL state change.
 * IN-OUT setting is set to OUTPUT at fixed-regulator probe.
 */

&tlmm {
        ldo_gpio2: ldo_gpio2 {
                GPIO_CONFIG_PUD(AP,tlmm,49, FUNC_OUTPUT_HIGH, PULL_NONE);
        };
};

&smd {
	fixed_regulator2: fixed_regulator@2 {
		compatible = "regulator-fixed";
		regulator-name = "fixed_regulator2";
		gpio = <SEC_GPIO_REF(AP,tlmm,49) 0>;
		pinctrl-names = "default";
		pinctrl-0 = <&ldo_gpio2>;
		enable-active-high;regulator-boot-on;
	};
};


/* #include "../../regulator-fixed.dtsi" */          /* From regulator-fixed.py */
/* 
 * This pinctrl code is only for PULL state change.
 * IN-OUT setting is set to OUTPUT at fixed-regulator probe.
 */

&tlmm {
        ldo_gpio0: ldo_gpio0 {
                GPIO_CONFIG_PUD(AP,tlmm,47, FUNC_OUTPUT_HIGH, PULL_NONE);
        };
};

&smd {
	fixed_regulator0: fixed_regulator@0 {
		compatible = "regulator-fixed";
		regulator-name = "fixed_regulator0";
		gpio = <SEC_GPIO_REF(AP,tlmm,47) 0>;
		pinctrl-names = "default";
		pinctrl-0 = <&ldo_gpio0>;
		enable-active-high;regulator-boot-on;
	};
};


/* #include "../../regulator-fixe-3.dtsi" */         /* From regulator-fixed.py */
/* 
 * This pinctrl code is only for PULL state change.
 * IN-OUT setting is set to OUTPUT at fixed-regulator probe.
 */

&tlmm {
        ldo_gpio3: ldo_gpio3 {
                GPIO_CONFIG_PUD(AP,tlmm,24, FUNC_OUTPUT_HIGH, PULL_NONE);
        };
};

&smd {
	fixed_regulator3: fixed_regulator@3 {
		compatible = "regulator-fixed";
		regulator-name = "fixed_regulator3";
		gpio = <SEC_GPIO_REF(AP,tlmm,24) 0>;
		pinctrl-names = "default";
		pinctrl-0 = <&ldo_gpio3>;
		enable-active-high;regulator-boot-on;
	};
};


/* #include "../../s2mu106_vibrator.dtsi" */         /* From s2mu106_vibrator.py */
#define EXPAND(str) #str


&s2mu106 {
	s2mu106_haptic: s2mu106-haptic {
		compatible = "sec,s2mu106-haptic";
		status = "okay";
		haptic,operation_mode = <1>; // 0 : ERM_I2C, 1 : ERM_GPIO, 2 : LRA
		haptic,motor_en = <SEC_GPIO_REF(AP,tlmm,26) 0>;
		// frequency       alert low  mid  high  0  press release (multi_freq)
		haptic,frequency = <0>;
		haptic,normal_ratio = <0>;
		haptic,overdrive_ratio = <0>;
		haptic,motor_type = EXPAND(COINDC);

		haptic,motor_strength = EXPAND(0x64);
		samsung,steps = <6>;
		samsung,intensities = <0 2000 4000 6000 8000 10000>;
		samsung,haptic_intensities = <0 3400 4900 6500 8200 10000>;
	};
};

/* #include "../../s2mpb03.dtsi" */                  /* From s2mpb03.py */
&sw_i2c1 {
	#address-cells = <1>;
	#size-cells = <0>;
	status = "okay";
	s2mpb03_pmic_0: s2mpb03_pmic@56 {
		compatible = "samsung,s2mpb03pmic";
		reg = <0x56>;
		s2mpb03,wakeup;

		regulators {
			s2mpb03_0_l1: s2mpb03-ldo1 {
				regulator-name = "CAM0_s2mpb03-l1";
				regulator-min-microvolt = <1050000>;
				regulator-max-microvolt = <1050000>;
				
				 
			};

			s2mpb03_0_l2: s2mpb03-ldo2 {
				regulator-name = "CAM0_s2mpb03-l2";
				regulator-min-microvolt = <1200000>;
				regulator-max-microvolt = <1200000>;
				
				 
			};

			s2mpb03_0_l3: s2mpb03-ldo3 {
				regulator-name = "CAM0_s2mpb03-l3";
				regulator-min-microvolt = <1800000>;
				regulator-max-microvolt = <1800000>;
				
				 
			};

			s2mpb03_0_l4: s2mpb03-ldo4 {
				regulator-name = "CAM0_s2mpb03-l4";
				regulator-min-microvolt = <1200000>;
				regulator-max-microvolt = <1200000>;
				
				 
			};

			s2mpb03_0_l5: s2mpb03-ldo5 {
				regulator-name = "CAM0_s2mpb03-l5";
				regulator-min-microvolt = <2800000>;
				regulator-max-microvolt = <2800000>;
				
				 
			};

			s2mpb03_0_l6: s2mpb03-ldo6 {
				regulator-name = "CAM0_s2mpb03-l6";
				regulator-min-microvolt = <2800000>;
				regulator-max-microvolt = <2800000>;
				
				 
			};

			s2mpb03_0_l7: s2mpb03-ldo7 {
				regulator-name = "CAM0_s2mpb03-l7";
				regulator-min-microvolt = <2800000>;
				regulator-max-microvolt = <2800000>;
				
				 
			};
		};
	};
};

/* #include "../../s2mu106_muic.dtsi" */             /* From s2mu106_muic.py */
&smd {
	muic {
		new_factory;
		dcd_timeout;
	};
};

/* #include "../../gpio-pca953x.dtsi" */             /* From gpio-pca953x.py */
&tlmm {
	expander_reset_active: expander_reset_active {
		GPIO_CONFIG_PUD_DRV(AP,tlmm,45, FUNC_OUTPUT_HIGH, PULL_NONE, DRV_LV1);
	};
};


&sw_i2c0 {
	status = "okay";

	gpio_expander: pca953x@22 {
		compatible = "nxp,pca953x";
		reg = <0x22>;

		gpio-controller;
		#gpio-cells = <2>;

		pinctrl-names = "default";
		pinctrl-0 = <&expander_reset_active
		>;

		reset-gpios = <SEC_GPIO_REF(AP,tlmm,45) 1>;
		pca953x,gpio_start = <150>;
		pca953x,gpio_num = <24>;
	};
};


&fixed_regulator3 {
	regulator-name = "lcd_rst";
	/*regulator-boot-on;*/
};

&fixed_regulator0 {
	regulator-name = "lcd_vddi";
	/*regulator-boot-on;*/
};

&fixed_regulator1 {
	regulator-name = "lcd_vsp";
	/*regulator-boot-on;*/
};

&fixed_regulator2 {
	regulator-name = "lcd_vsn";
	/*regulator-boot-on;*/
};


&tlmm {
	panel_jb3_ubcon_active: panel_jb3_ubcon_active {
		GPIO_CONFIG_PUD_DRV(AP,tlmm,19, FUNC_INPUT, PULL_NONE, DRV_LV1);
	};
	panel_jb3_ubcon_suspend: panel_jb3_ubcon_suspend {
		GPIO_CONFIG_PUD_DRV(AP,tlmm,19, FUNC_INPUT, PULL_NONE, DRV_LV1);
	};
};

&tlmm {
	panel_jb3_esd_1_active: panel_jb3_esd_1_active {
		GPIO_CONFIG_PUD_DRV(AP,tlmm,35, FUNC_INPUT, PULL_NONE, DRV_LV1);
	};
	panel_jb3_esd_1_suspend: panel_jb3_esd_1_suspend {
		GPIO_CONFIG_PUD_DRV(AP,tlmm,35, FUNC_INPUT, PULL_NONE, DRV_LV1);
	};
};

&qupv3_se2_i2c {
	status = "ok";

	display_buck@11{
		compatible = "s2dps01a01,display_backlight";
		reg = <0x66>;
	};
};


&fixed_regulator3 {
	regulator-name = "lcd_rst";
	/*regulator-boot-on;*/
};

&fixed_regulator0 {
	regulator-name = "lcd_vddi";
	/*regulator-boot-on;*/
};

&fixed_regulator1 {
	regulator-name = "lcd_vsp";
	/*regulator-boot-on;*/
};

&fixed_regulator2 {
	regulator-name = "lcd_vsn";
	/*regulator-boot-on;*/
};


&tlmm {
	panel_fbm_ubcon_active: panel_fbm_ubcon_active {
		GPIO_CONFIG_PUD_DRV(AP,tlmm,19, FUNC_INPUT, PULL_NONE, DRV_LV1);
	};
	panel_fbm_ubcon_suspend: panel_fbm_ubcon_suspend {
		GPIO_CONFIG_PUD_DRV(AP,tlmm,19, FUNC_INPUT, PULL_NONE, DRV_LV1);
	};
};

&tlmm {
	panel_fbm_esd_1_active: panel_fbm_esd_1_active {
		GPIO_CONFIG_PUD_DRV(AP,tlmm,35, FUNC_INPUT, PULL_NONE, DRV_LV1);
	};
	panel_fbm_esd_1_suspend: panel_fbm_esd_1_suspend {
		GPIO_CONFIG_PUD_DRV(AP,tlmm,35, FUNC_INPUT, PULL_NONE, DRV_LV1);
	};
};

&qupv3_se2_i2c {
	status = "ok";

	display_buck@11{
		compatible = "s2dps01a01,display_backlight";
		reg = <0x66>;
	};
};


&fixed_regulator3 {
	regulator-name = "lcd_rst";
	/*regulator-boot-on;*/
};

&fixed_regulator0 {
	regulator-name = "lcd_vddi";
	/*regulator-boot-on;*/
};

&fixed_regulator1 {
	regulator-name = "lcd_vsp";
	/*regulator-boot-on;*/
};

&fixed_regulator2 {
	regulator-name = "lcd_vsn";
	/*regulator-boot-on;*/
};


&tlmm {
	panel_606_ubcon_active: panel_606_ubcon_active {
		GPIO_CONFIG_PUD_DRV(AP,tlmm,19, FUNC_INPUT, PULL_NONE, DRV_LV1);
	};
	panel_606_ubcon_suspend: panel_606_ubcon_suspend {
		GPIO_CONFIG_PUD_DRV(AP,tlmm,19, FUNC_INPUT, PULL_NONE, DRV_LV1);
	};
};

&tlmm {
	panel_606_esd_1_active: panel_606_esd_1_active {
		GPIO_CONFIG_PUD_DRV(AP,tlmm,35, FUNC_INPUT, PULL_NONE, DRV_LV1);
	};
	panel_606_esd_1_suspend: panel_606_esd_1_suspend {
		GPIO_CONFIG_PUD_DRV(AP,tlmm,35, FUNC_INPUT, PULL_NONE, DRV_LV1);
	};
};

&qupv3_se2_i2c {
	status = "ok";

	display_buck@11{
		compatible = "s2dps01a01,display_backlight";
		reg = <0x66>;
	};
};

/* #include "../../s2mu106_fuelgauge.dtsi" */        /* From s2mu106_fuelgauge.py */

&tlmm {
	fg_alert_default: fg_alert_default {
		GPIO_CONFIG_PUD(AP,tlmm,46, FUNC_INPUT_WAKEUP, PULL_NONE);
	};
};

&qupv3_se1_i2c {
	status = "okay";

	s2mu106_fuelgauge: s2mu106-fuelgauge@3B {
		compatible = "samsung,s2mu106-fuelgauge";
		reg = <0x3B>;
		pinctrl-names = "default";
		pinctrl-0 = <&fg_alert_default>;
		fuelgauge,fuel_int = <SEC_GPIO_REF(AP,tlmm,46) 0>;
		fuelgauge,fuel_alert_soc = <1>;
		fuelgauge,fuel_alert_vol = <3300>;
		fuelgauge,low_temp_limit = <100>;
		fuelgauge,low_voltage_limit_lowtemp = <3100>;
		fuelgauge,capacity_max = <1000>;
		fuelgauge,capacity_max_margin = <200>;
		fuelgauge,capacity_min = <0>;
		fuelgauge,capacity_calculation_type = <28>;
		fuelgauge,capacity_full = <4370>;
		fuelgauge,type_str = "SDI";
		fuelgauge,fg_log_enable = <1>;

		fuelgauge,bat_id_gpio = <
				SEC_GPIO_REF(AP,tlmm,104) 0  /* BAT_ID_2 */
				SEC_GPIO_REF(AP,tlmm,54) 0  /* BAT_ID_1 */
				>;
	};
};

&smd {
	battery {
		battery,fgsrc_switch_name = "s2mu106-fuelgauge"; /* Fuelgauge voltage source */
	};
};

/* /home/dpi/qb5_8815/workspace/P4_1716/android/kernel/kmodule/battery/suwon/fuelgauge/s2mu106/s2mu106_fuelgauge.a23.dtsi */

&s2mu106_fuelgauge {
	fuelgauge,capacity_full = <5000>;
	fuelgauge,low_voltage_limit_lowtemp = <3100>;
	fuelgauge,low_voltage_recover_lowtemp = <3550>;
	fuelgauge,i_socr_coeff = <80>;
	fuelgauge,low_t_compen_coeff = <180>;
};

&smd {
	battery_params {
		battery,id = <3>; /* default ID */
		/*
		 * BAT_ID_1/BAT_ID_2
		 * 11: SDI, 10: ATL2
		 * 01: ATL1, 00: LGES
		 */

		/* 11: SDI */
		battery3,battery_data = <
			/***** battery data for 4.38 *****/
			/* battery,battery_table3 */
			193 11 69 11 202 10 78 10 209 9
			87 9 227 8 119 8 20 8 187 7
			63 7 239 6 185 6 141 6 106 6
			76 6 32 6 245 5 189 5 137 5
			66 5 125 1 219 8 110 8 0 8
			146 7 37 7 183 6 74 6 220 5
			110 5 1 5 147 4 37 4 184 3
			74 3 221 2 111 2 1 2 148 1
			38 1 185 0 75 0 226 15
			/* battery,battery_table4 */
			16 16 16 16 34 34 34 33 33 33
			33 33 33 33 33 34 34 34 35 36
			39 154
			/* battery,batcap */
			0xf0 0x46 0x4d 0x0d  /* [0x0E] [0x0F] [0x10] [0x11] */
			/* battery,accum */
			0x00 0x8 /* [0x44] [0x45] */
			/* battery,soc_arr_val */
			11070 10535 10000 9465 8930 8394 7859 7324 6789 6253
			5718 5183 4648 4112 3577 3042 2507 1971 1436 901
			366 (-149)
			/* battery,ocv_arr_val */
			44694 44089 43484 42879 42272 41676 41108 40580 40098 39661
			39056 38669 38402 38188 38019 37872 37655 37445 37172 36919
			36575 31862
			/* battery,tuning */
			0x00

			/***** battery data for 4.36 *****/
			/* battery,battery_table3 */
			193 11 69 11 202 10 78 10 209 9
			87 9 227 8 119 8 20 8 187 7
			63 7 239 6 185 6 141 6 106 6
			76 6 32 6 245 5 189 5 137 5
			66 5 125 1 243 8 132 8 21 8
			165 7 54 7 198 6 87 6 232 5
			120 5 9 5 154 4 42 4 187 3
			75 3 220 2 109 2 253 1 142 1
			31 1 175 0 64 0 213 15
			/* battery,battery_table4 */
			16 16 16 16 34 34 34 33 33 33
			33 33 33 33 33 34 34 34 35 36
			39 154
			/* battery,batcap */
			0xd0 0x45 0x17 0x0d  /* [0x0E] [0x0F] [0x10] [0x11] */
			/* battery,accum */
			0x00 0x8 /* [0x44] [0x45] */
			/* battery,soc_arr_val */
			11188 10645 10101 9557 9013 8469 7925 7381 6838 6294
			5750 5206 4662 4118 3574 3031 2487 1943 1399 855
			311 (-212)
			/* battery,ocv_arr_val */
			44694 44089 43484 42879 42272 41676 41108 40580 40098 39661
			39056 38669 38402 38188 38019 37872 37655 37445 37172 36919
			36575 31862
			/* battery,tuning */
			0x00

			/***** battery data for 4.34 *****/
			/* battery,battery_table3 */
			193 11 69 11 202 10 78 10 209 9
			87 9 227 8 119 8 20 8 187 7
			63 7 239 6 185 6 141 6 106 6
			76 6 32 6 245 5 189 5 137 5
			66 5 125 1 29 9 172 8 58 8
			201 7 88 7 230 6 117 6 3 6
			146 5 32 5 175 4 62 4 204 3
			91 3 233 2 120 2 7 2 149 1
			36 1 178 0 65 0 212 15
			/* battery,battery_table4 */
			16 16 16 16 34 34 34 33 33 33
			33 33 33 33 33 34 34 34 35 36
			39 154
			/* battery,batcap */
			0x90 0x44 0xDB 0x0C /* [0x0E] [0x0F] [0x10] [0x11] */
			/* battery,accum */
			0x00 0x8 /* [0x44] [0x45] */
			/* battery,soc_arr_val */
			11392 10839 10285 9731 9177 8624 8070 7516 6962 6408
			5855 5301 4747 4193 3640 3086 2532 1978 1424 871
			317 (-215)
			/* battery,ocv_arr_val */
			44694 44089 43484 42879 42272 41676 41108 40580 40098 39661
			39056 38669 38402 38188 38019 37872 37655 37445 37172 36919
			36575 31862
			/* battery,tuning */
			0x00

			/***** battery data for 4.32 *****/
			/* battery,battery_table3 */
			193 11 69 11 202 10 78 10 209 9
			87 9 227 8 119 8 20 8 187 7
			63 7 239 6 185 6 141 6 106 6
			76 6 32 6 245 5 189 5 137 5
			66 5 125 1 72 9 213 8 97 8
			238 7 122 7 7 7 147 6 32 6
			172 5 57 5 197 4 82 4 222 3
			107 3 247 2 132 2 16 2 157 1
			41 1 182 0 66 0 211 15
			/* battery,battery_table4 */
			16 16 16 16 34 34 34 33 33 33
			33 33 33 33 33 34 34 34 35 36
			39 154
			/* battery,batcap */
			0x50 0x43 0x9F 0x0C /* [0x0E] [0x0F] [0x10] [0x11] */
			/* battery,accum */
			0x00 0x8 /* [0x44] [0x45] */
			/* battery,soc_arr_val */
			11604 11040 10476 9912 9348 8784 8220 7656 7091 6527
			5963 5399 4835 4271 3707 3143 2579 2015 1451 887
			323 (-219)
			/* battery,ocv_arr_val */
			44694 44089 43484 42879 42272 41676 41108 40580 40098 39661
			39056 38669 38402 38188 38019 37872 37655 37445 37172 36919
			36575 31862
			/* battery,tuning */
			0x00

			/***** battery data for 4.27 *****/
			/* battery,battery_table3 */
			193 11 69 11 202 10 78 10 209 9
			87 9 227 8 119 8 20 8 187 7
			63 7 239 6 185 6 141 6 106 6
			76 6 32 6 245 5 189 5 137 5
			66 5 125 1 185 9 64 9 199 8
			78 8 213 7 92 7 227 6 106 6
			241 5 120 5 255 4 134 4 13 4
			148 3 27 3 162 2 41 2 176 1
			55 1 190 0 69 0 209 15
			/* battery,battery_table4 */
			16 16 16 16 34 34 34 33 33 33
			33 33 33 33 33 34 34 34 35 36
			39 154
			/* battery,batcap */
			0x44 0x40 0x0C 0x0C /* [0x0E] [0x0F] [0x10] [0x11] */
			/* battery,accum */
			0x00 0x8 /* [0x44] [0x45] */
			/* battery,soc_arr_val */
			12154 11563 10972 10382 9791 9200 8609 8018 7428 6837
			6246 5655 5064 4474 3883 3292 2701 2110 1520 929
			338 (-230)
			/* battery,ocv_arr_val */
			44694 44089 43484 42879 42272 41676 41108 40580 40098 39661
			39056 38669 38402 38188 38019 37872 37655 37445 37172 36919
			36575 31862
			/* battery,tuning */
			0x00
			>;
		/* 10: ATL STS */
		battery2,battery_data = <
			/***** battery data for 4.38 *****/
			/* battery,battery_table3 */
			200 11 79 11 213 10 92 10 221 9
			97 9 233 8 123 8 23 8 191 7
			72 7 242 6 187 6 143 6 109 6
			81 6 34 6 247 5 191 5 138 5
			59 5 236 0 221 8 111 8 0 8
			145 7 35 7 180 6 70 6 215 5
			105 5 250 4 139 4 29 4 174 3
			64 3 209 2 99 2 244 1 133 1
			23 1 168 0 58 0 211 15
			/* battery,battery_table4 */
			15 15 15 15 30 31 31 31 32 32
			31 31 32 32 32 32 32 33 33 33
			34 154
			/* battery,batcap */
			0x50 0x46 0x2f 0x0d  /* [0x0E] [0x0F] [0x10] [0x11] */
			/* battery,accum */
			0x00 0x8 /* [0x44] [0x45] */
			/* battery,soc_arr_val */
			11080 10540 10000 9460 8920 8380 7840 7301 6761 6221
			5681 5141 4601 4061 3521 2981 2442 1902 1362 822
			282 (-222)
			/* battery,ocv_arr_val */
			44726 44133 43541 42948 42332 41722 41140 40601 40114 39683
			39101 38681 38412 38199 38031 37894 37665 37455 37182 36923
			36538 31154
			/* battery,tuning */
			0x00
			/***** battery data for 4.36 *****/
			/* battery,battery_table3 */
			200 11 79 11 213 10 92 10 221 9
			97 9 233 8 123 8 23 8 191 7
			72 7 242 6 187 6 143 6 109 6
			81 6 34 6 247 5 191 5 138 5
			59 5 236 0 3 9 146 8 34 8
			177 7 65 7 209 6 96 6 240 5
			127 5 15 5 159 4 46 4 190 3
			77 3 221 2 109 2 252 1 140 1
			27 1 171 0 59 0 210 15
			/* battery,battery_table4 */
			15 15 15 15 30 31 31 31 32 32
			31 31 32 32 32 32 32 33 33 33
			34 154
			/* battery,batcap */
			0x2C 0x45 0xF8 0x0C  /* [0x0E] [0x0F] [0x10] [0x11] */
			/* battery,accum */
			0x00 0x8 /* [0x44] [0x45] */
			/* battery,soc_arr_val */
			11262 10714 10165 9616 9067 8518 7970 7421 6872 6323
			5775 5226 4677 4128 3579 3031 2482 1933 1384 835
			287 (-226)
			/* battery,ocv_arr_val */
			44726 44133 43541 42948 42332 41722 41140 40601 40114 39683
			39101 38681 38412 38199 38031 37894 37665 37455 37182 36923
			36538 31154
			/* battery,tuning */
			0x00

			/***** battery data for 4.34 *****/
			/* battery,battery_table3 */
			200 11 79 11 213 10 92 10 221 9
			97 9 233 8 123 8 23 8 191 7
			72 7 242 6 187 6 143 6 109 6
			81 6 34 6 247 5 191 5 138 5
			59 5 236 0 46 9 188 8 73 8
			215 7 100 7 241 6 127 6 12 6
			154 5 39 5 181 4 66 4 208 3
			93 3 235 2 120 2 6 2 147 1
			33 1 174 0 60 0 209 15
			/* battery,battery_table4 */
			15 15 15 15 30 31 31 31 32 32
			31 31 32 32 32 32 32 33 33 33
			34 154
			/* battery,batcap */
			0xE4 0x43 0xBA 0x0C/* [0x0E] [0x0F] [0x10] [0x11] */
			/* battery,accum */
			0x00 0x8 /* [0x44] [0x45] */
			/* battery,soc_arr_val */
			11475 10916 10357 9797 9238 8679 8120 7561 7002 6443
			5883 5324 4765 4206 3647 3088 2529 1969 1410 851
			292 (-230)
			/* battery,ocv_arr_val */
			44726 44133 43541 42948 42332 41722 41140 40601 40114 39683
			39101 38681 38412 38199 38031 37894 37665 37455 37182 36923
			36538 31154
			/* battery,tuning */
			0x00

			/***** battery data for 4.32 *****/
			/* battery,battery_table3 */
			200 11 79 11 213 10 92 10 221 9
			97 9 233 8 123 8 23 8 191 7
			72 7 242 6 187 6 143 6 109 6
			81 6 34 6 247 5 191 5 138 5
			59 5 236 0 96 9 235 8 118 8
			1 8 140 7 23 7 162 6 45 6
			184 5 67 5 206 4 89 4 229 3
			112 3 251 2 134 2 17 2 156 1
			39 1 178 0 61 0 208 15
			/* battery,battery_table4 */
			15 15 15 15 30 31 31 31 32 32
			31 31 32 32 32 32 32 33 33 33
			34 154
			/* battery,batcap */
			0x7C 0x42 0x77 0x0C/* [0x0E] [0x0F] [0x10] [0x11] */
			/* battery,accum */
			0x00 0x8 /* [0x44] [0x45] */
			/* battery,soc_arr_val */
			11718 11147 10576 10005 9434 8863 8292 7721 7150 6579
			6008 5437 4866 4295 3724 3153 2582 2011 1440 869
			298 (-235)
			/* battery,ocv_arr_val */
			44726 44133 43541 42948 42332 41722 41140 40601 40114 39683
			39101 38681 38412 38199 38031 37894 37665 37455 37182 36923
			36538 31154
			/* battery,tuning */
			0x00

			/***** battery data for 4.27 *****/
			/* battery,battery_table3 */
			200 11 79 11 213 10 92 10 221 9
			97 9 233 8 123 8 23 8 191 7
			72 7 242 6 187 6 143 6 109 6
			81 6 34 6 247 5 191 5 138 5
			59 5 236 0 208 9 85 9 219 8
			97 8 230 7 108 7 241 6 119 6
			253 5 130 5 8 5 142 4 19 4
			153 3 30 3 164 2 42 2 175 1
			53 1 186 0 64 0 206 15
			/* battery,battery_table4 */
			15 15 15 15 30 31 31 31 32 32
			31 31 32 32 32 32 32 33 33 33
			34 154
			/* battery,batcap */
			0x84 0x3F 0xE8 0x0B/* [0x0E] [0x0F] [0x10] [0x11] */
			/* battery,accum */
			0x00 0x8 /* [0x44] [0x45] */
			/* battery,soc_arr_val */
			12265 11667 11070 10472 9874 9277 8679 8082 7484 6886
			6289 5691 5093 4496 3898 3300 2703 2105 1507 910
			312 (-246)
			/* battery,ocv_arr_val */
			44726 44133 43541 42948 42332 41722 41140 40601 40114 39683
			39101 38681 38412 38199 38031 37894 37665 37455 37182 36923
			36538 31154
			/* battery,tuning */
			0x00
			>;
		/* 01: ATL1 */
		battery1,battery_data = <
			/***** battery data for 4.38 *****/
			/* battery,battery_table3 */
			189 11 71 11 209 10 90 10 224 9
			103 9 243 8 134 8 36 8 195 7
			65 7 251 6 196 6 151 6 115 6
			80 6 26 6 239 5 173 5 139 5
			191 4 157 1 222 8 111 8 0 8
			145 7 34 7 179 6 68 6 213 5
			102 5 247 4 136 4 25 4 170 3
			59 3 204 2 93 2 237 1 126 1
			15 1 160 0 49 0 232 15
			/* battery,battery_table4 */
			50 50 50 50 102 102 102 101 101 101
			101 101 101 102 102 102 102 102 102 103
			104 154
			/* battery,batcap */
			0x08 0x46 0x21 0x0d  /* [0x0E] [0x0F] [0x10] [0x11] */
			/* battery,accum */
			0x00 0x8 /* [0x44] [0x45] */
			/* battery,soc_arr_val */
			11084 10542 10000 9458 8916 8373 7831 7289 6747 6205
			5663 5120 4578 4036 3494 2952 2410 1867 1325 783
			241 (-117)
			/* battery,ocv_arr_val */
			44674 44096 43519 42941 42343 41751 41184 40656 40175 39701
			39067 38725 38457 38238 38061 37890 37627 37415 37095 36927
			35930 32017
			/* battery,tuning */
			0x00

			/***** battery data for 4.36 *****/
			/* battery,battery_table3 */
			189 11 71 11 209 10 90 10 224 9
			103 9 243 8 134 8 36 8 195 7
			65 7 251 6 196 6 151 6 115 6
			80 6 26 6 239 5 173 5 139 5
			191 4 157 1 49 9 189 8 74 8
			214 7 99 7 239 6 124 6 8 6
			149 5 33 5 174 4 58 4 199 3
			83 3 224 2 108 2 249 1 133 1
			18 1 158 0 43 0 223 15
			/* battery,battery_table4 */
			50 50 50 51 102 102 102 101 101 101
			101 101 101 102 102 102 102 102 102 103
			104 154
			/* battery,batcap */
			0xA8 0x44 0xDF 0x0C/* [0x0E] [0x0F] [0x10] [0x11] */
			/* battery,accum */
			0x00 0x8 /* [0x44] [0x45] */
			/* battery,soc_arr_val */
			11265 10712 10159 9606 9053 8500 7947 7394 6841 6288
			5736 5183 4630 4077 3524 2971 2418 1865 1312 759
			206 (-160)
			/* battery,ocv_arr_val */
			44674 44096 43519 42941 42343 41751 41184 40656 40175 39701
			39067 38725 38457 38238 38061 37890 37627 37415 37095 36927
			35930 32017
			/* battery,tuning */
			0x00

			/***** battery data for 4.34 *****/
			/* battery,battery_table3 */
			189 11 71 11 209 10 90 10 224 9
			103 9 243 8 134 8 36 8 195 7
			65 7 251 6 196 6 151 6 115 6
			80 6 26 6 239 5 173 5 139 5
			191 4 157 1 49 9 189 8 74 8
			214 7 99 7 239 6 124 6 8 6
			149 5 33 5 174 4 58 4 199 3
			83 3 224 2 108 2 249 1 133 1
			18 1 158 0 43 0 223 15
			/* battery,battery_table4 */
			50 50 50 51 102 102 102 101 101 101
			101 101 101 102 102 102 102 102 102 103
			104 154
			/* battery,batcap */
			0x54 0x43 0x9F 0x0C/* [0x0E] [0x0F] [0x10] [0x11] */
			/* battery,accum */
			0x00 0x8 /* [0x44] [0x45] */
			/* battery,soc_arr_val */
			11487 10924 10360 9796 9232 8668 8104 7540 6976 6413
			5849 5285 4721 4157 3593 3029 2465 1902 1338 774
			210 (-163)
			/* battery,ocv_arr_val */
			44674 44096 43519 42941 42343 41751 41184 40656 40175 39701
			39067 38725 38457 38238 38061 37890 37627 37415 37095 36927
			35930 32017
			/* battery,tuning */
			0x00

			/***** battery data for 4.32 *****/
			/* battery,battery_table3 */
			189 11 71 11 209 10 90 10 224 9
			103 9 243 8 134 8 36 8 195 7
			65 7 251 6 196 6 151 6 115 6
			80 6 26 6 239 5 173 5 139 5
			191 4 157 1 96 9 234 8 116 8
			255 7 137 7 19 7 157 6 39 6
			178 5 60 5 198 4 80 4 218 3
			100 3 239 2 121 2 3 2 141 1
			23 1 162 0 44 0 222 15
			/* battery,battery_table4 */
			50 50 50 51 102 102 102 101 101 101
			101 101 101 102 102 102 102 102 102 103
			104 154
			/* battery,batcap */
			0x0 0x42 0x60 0x0C/* [0x0E] [0x0F] [0x10] [0x11] */
			/* battery,accum */
			0x00 0x8 /* [0x44] [0x45] */
			/* battery,soc_arr_val */
			11719 11143 10568 9993 9418 8842 8267 7692 7117 6542
			5966 5391 4816 4241 3665 3090 2515 1940 1365 789
			214 (-166)
			/* battery,ocv_arr_val */
			44674 44096 43519 42941 42343 41751 41184 40656 40175 39701
			39067 38725 38457 38238 38061 37890 37627 37415 37095 36927
			35930 32017
			/* battery,tuning */
			0x00

			/***** battery data for 4.27 *****/
			/* battery,battery_table3 */
			189 11 71 11 209 10 90 10 224 9
			103 9 243 8 134 8 36 8 195 7
			65 7 251 6 196 6 151 6 115 6
			80 6 26 6 239 5 173 5 139 5
			191 4 157 1 212 9 89 9 221 8
			98 8 230 7 107 7 239 6 116 6
			248 5 125 5 1 5 134 4 10 4
			143 3 19 3 152 2 28 2 160 1
			37 1 169 0 46 0 220 15
			/* battery,battery_table4 */
			50 50 50 51 102 102 102 101 101 101
			101 101 101 102 102 102 102 102 102 103
			104 154
			/* battery,batcap */
			0xF4 0x3E 0xCD 0x0B/* [0x0E] [0x0F] [0x10] [0x11] */
			/* battery,accum */
			0x00 0x8 /* [0x44] [0x45] */
			/* battery,soc_arr_val */
			12286 11683 11079 10476 9873 9270 8667 8064 7461 6858
			6255 5652 5049 4446 3843 3240 2637 2034 1431 828
			224 (-174)
			/* battery,ocv_arr_val */
			44674 44096 43519 42941 42343 41751 41184 40656 40175 39701
			39067 38725 38457 38238 38061 37890 37627 37415 37095 36927
			35930 32017
			/* battery,tuning */
			0x00
			>;
		/* 00: LGES */
		battery0,battery_data = <
			/***** battery data for 4.38 *****/
			/* battery,battery_table3 */
			202 11 78 11 210 10 86 10 215 9
			89 9 226 8 115 8 12 8 171 7
			47 7 232 6 178 6 135 6 100 6
			62 6 9 6 217 5 145 5 127 5
			248 3 158 1 225 8 112 8 0 8
			144 7 31 7 175 6 62 6 206 5
			93 5 237 4 125 4 12 4 156 3
			43 3 187 2 74 2 218 1 106 1
			249 0 137 0 24 0 236 15
			/* battery,battery_table4 */
			13 13 13 13 27 27 27 27 27 26
			26 26 26 26 27 27 27 27 28 30
			34 154
			/* battery,batcap */
			0x28 0x45 0xf7 0x0c  /* [0x0E] [0x0F] [0x10] [0x11] */
			/* battery,accum */
			0x00 0x8 /* [0x44] [0x45] */
			/* battery,soc_arr_val */
			11098 10549 10000 9451 8902 8353 7804 7255 6706 6157
			5608 5059 4511 3962 3413 2864 2315 1766 1217 668
			119 (-98)
			/* battery,ocv_arr_val */
			44735 44129 43524 42918 42297 41686 41102 40559 40060 39587
			38982 38633 38371 38159 37987 37802 37542 37311 36956 36871
			34962 32023
			/* battery,tuning */
			0x00

			/***** battery data for 4.33 *****/
			/* battery,battery_table3 */
			202 11 78 11 210 10 86 10 215 9
			89 9 226 8 115 8 12 8 171 7
			47 7 232 6 178 6 135 6 100 6
			62 6 9 6 217 5 145 5 127 5
			248 3 158 1 225 8 112 8 0 8
			144 7 31 7 175 6 62 6 206 5
			93 5 237 4 125 4 12 4 156 3
			43 3 187 2 74 2 218 1 106 1
			249 0 137 0 24 0 236 15
			/* battery,battery_table4 */
			13 13 13 13 27 27 27 27 27 26
			26 26 26 26 27 27 27 27 28 30
			34 154
			/* battery,batcap */
			0x28 0x45 0xf7 0x0c  /* [0x0E] [0x0F] [0x10] [0x11] */
			/* battery,accum */
			0x00 0x8 /* [0x44] [0x45] */
			/* battery,soc_arr_val */
			11098 10549 10000 9451 8902 8353 7804 7255 6706 6157
			5608 5059 4511 3962 3413 2864 2315 1766 1217 668
			119 (-98)
			/* battery,ocv_arr_val */
			44735 44129 43524 42918 42297 41686 41102 40559 40060 39587
			38982 38633 38371 38159 37987 37802 37542 37311 36956 36871
			34962 32023
			/* battery,tuning */
			0x00

			/***** battery data for 4.31 *****/
			/* battery,battery_table3 */
			233 10 108 10 239 9 123 9 11 9
			162 8 62 8 229 7 150 7 35 7
			216 6 166 6 126 6 94 6 68 6
			36 6 250 5 201 5 139 5 120 5
			98 3 90 1 159 8 49 8 195 7
			85 7 232 6 122 6 12 6 158 5
			49 5 195 4 85 4 231 3 122 3
			12 3 158 2 48 2 195 1 85 1
			231 0 121 0 12 0 136 15
			/* battery,battery_table4 */
			10 10 10 10 54 54 54 54 54 54
			54 54 55 55 56 56 56 57 59 63
			76 101
			/* battery,batcap */
			0xF8 0x49 0xCB 0x0E /* [0x0E] [0x0F] [0x10] [0x11] */
			/* battery,accum */
			0x00 0x8 /* [0x44] [0x45] */
			/* battery,soc_arr_val */
			10774 10238 9702 9166 8630 8094 7559 7023 6487 5951
			5415 4879 4343 3807 3271 2736 2200 1664 1128 592
			56 (-586)
			/* battery,ocv_arr_val */
			43638 43028 42419 41849 41305 40789 40302 39869 39480 38923
			38557 38311 38115 37959 37830 37674 37472 37233 36929 36837
			34229 31691
			/* battery,tuning */
			0x00

			/***** battery data for 4.29 *****/
			/* battery,battery_table3 */
			233 10 108 10 239 9 123 9 11 9
			162 8 62 8 229 7 150 7 35 7
			216 6 166 6 126 6 94 6 68 6
			36 6 250 5 201 5 139 5 120 5
			98 3 90 1 203 8 91 8 235 7
			123 7 11 7 155 6 43 6 187 5
			75 5 219 4 107 4 251 3 139 3
			27 3 171 2 60 2 204 1 92 1
			236 0 124 0 12 0 136 15
			/* battery,battery_table4 */
			10 10 10 10 54 54 54 54 54 54
			54 54 55 55 56 56 56 57 59 63
			76 101
			/* battery,batcap */
			0x84 0x48 0x80 0x0E /* [0x0E] [0x0F] [0x10] [0x11] */
			/* battery,accum */
			0x00 0x8 /* [0x44] [0x45] */
			/* battery,soc_arr_val */
			10990 10443 9897 9350 8803 8257 7710 7163 6617 6070
			5524 4977 4430 3884 3337 2790 2244 1697 1150 604
			57 (-588)
			/* battery,ocv_arr_val */
			43638 43028 42419 41849 41305 40789 40302 39869 39480 38923
			38557 38311 38115 37959 37830 37674 37472 37233 36929 36837
			34229 31691
			/* battery,tuning */
			0x00

			/***** battery data for 4.24 *****/
			/* battery,battery_table3 */
			233 10 108 10 239 9 123 9 11 9
			162 8 62 8 229 7 150 7 35 7
			216 6 166 6 126 6 94 6 68 6
			36 6 250 5 201 5 139 5 120 5
			98 3 90 1 54 9 192 8 75 8
			214 7 97 7 235 6 118 6 1 6
			139 5 22 5 161 4 44 4 182 3
			65 3 204 2 87 2 225 1 108 1
			247 0 130 0 12 0 136 15
			/* battery,battery_table4 */
			10 10 10 10 54 54 54 54 54 54
			54 54 55 55 56 56 56 57 59 63
			76 101
			/* battery,batcap */
			0x3C 0x45 0xD8 0x0D /* [0x0E] [0x0F] [0x10] [0x11] */
			/* battery,accum */
			0x00 0x8 /* [0x44] [0x45] */
			/* battery,soc_arr_val */
			11511 10939 10366 9793 9221 8648 8076 7503 6931 6358
			5786 5213 4640 4068 3495 2923 2350 1778 1205 632
			60 (-592)
			/* battery,ocv_arr_val */
			43638 43028 42419 41849 41305 40789 40302 39869 39480 38923
			38557 38311 38115 37959 37830 37674 37472 37233 36929 36837
			34229 31691
			/* battery,tuning */
			0x00
			>;
	};
};


&fixed_regulator3 {
	regulator-name = "lcd_rst";
	/*regulator-boot-on;*/
};

&fixed_regulator0 {
	regulator-name = "lcd_vddi";
	/*regulator-boot-on;*/
};

&fixed_regulator1 {
	regulator-name = "lcd_vsp";
	/*regulator-boot-on;*/
};

&fixed_regulator2 {
	regulator-name = "lcd_vsn";
	/*regulator-boot-on;*/
};


&tlmm {
	panel_67a_ubcon_active: panel_67a_ubcon_active {
		GPIO_CONFIG_PUD_DRV(AP,tlmm,19, FUNC_INPUT, PULL_NONE, DRV_LV1);
	};
	panel_67a_ubcon_suspend: panel_67a_ubcon_suspend {
		GPIO_CONFIG_PUD_DRV(AP,tlmm,19, FUNC_INPUT, PULL_NONE, DRV_LV1);
	};
};

&tlmm {
	panel_67a_esd_1_active: panel_67a_esd_1_active {
		GPIO_CONFIG_PUD_DRV(AP,tlmm,35, FUNC_INPUT, PULL_NONE, DRV_LV1);
	};
	panel_67a_esd_1_suspend: panel_67a_esd_1_suspend {
		GPIO_CONFIG_PUD_DRV(AP,tlmm,35, FUNC_INPUT, PULL_NONE, DRV_LV1);
	};
};

&qupv3_se2_i2c {
	status = "ok";

	display_buck@11{
		compatible = "s2dps01a01,display_backlight";
		reg = <0x66>;
	};
};

/* #include "../../sec_thermistor.dtsi" */           /* From sec_thermistor.py */
&smd {
	sec_ap_thermistor: sec_thermistor@0 {
		compatible = "samsung,sec-thermistor";
		status = "okay";
		thermistor_name = "sec-ap-thermistor";
		id = <0>;

		io-channels = SEC_ADC(pm6125_vadc,0x52);
		io-channel-names = "ap_therm";
		io-channel-ranges;
	};
};

&pm6125_vadc {
	ap_therm {
		reg = SEC_ADC_NUM(pm6125_vadc,0x52);
		label = "ap_therm";
		qcom,ratiometric;
		qcom,hw-settle-time = <200>;
		qcom,pre-scaling = <1 1>;

		qcom,decimation = <840>;
		qcom,avg-samples = <8>;
	};
};
/* #include "../../sec_thermistor-2.dtsi" */         /* From sec_thermistor.py */
&smd {
	sec_pa_thermistor: sec_thermistor@2 {
		compatible = "samsung,sec-thermistor";
		status = "okay";
		thermistor_name = "sec-pa-thermistor";
		id = <2>;

		io-channels = SEC_ADC(pm6125_vadc,0x4D);
		io-channel-names = "pa_therm";
		io-channel-ranges;
	};
};

&pm6125_vadc {
	pa_therm {
		reg = SEC_ADC_NUM(pm6125_vadc,0x4D);
		label = "pa_therm";
		qcom,ratiometric;
		qcom,hw-settle-time = <200>;
		qcom,pre-scaling = <1 1>;

		qcom,decimation = <840>;
		qcom,avg-samples = <8>;
	};
};
/* #include "../../sec_thermistor-1.dtsi" */         /* From sec_thermistor.py */
&smd {
	sec_wf_thermistor: sec_thermistor@1 {
		compatible = "samsung,sec-thermistor";
		status = "okay";
		thermistor_name = "sec-wf-thermistor";
		id = <1>;

		io-channels = SEC_ADC(pm6125_vadc,0x53);
		io-channel-names = "wf_therm";
		io-channel-ranges;
	};
};

&pm6125_vadc {
	wf_therm {
		reg = SEC_ADC_NUM(pm6125_vadc,0x53);
		label = "wf_therm";
		qcom,ratiometric;
		qcom,hw-settle-time = <200>;
		qcom,pre-scaling = <1 1>;

		qcom,decimation = <840>;
		qcom,avg-samples = <8>;
	};
};
/* /home/dpi/qb5_8815/workspace/P4_1716/android/kernel/kmodule/hwmon/sec_thermistor/sec_thermistor_qc.a23.dtsi */
&pm6125_vadc {
	/delete-node/ camera_flash_therm;
	/delete-node/ emmc_ufs_therm;
};

&pm6125_adc_tm_iio {
	/delete-node/ camera_flash_therm;
	/delete-node/ emmc_ufs_therm;
};

&pm6125_gpios {
    /delete-node/ camera_therm;
    /delete-node/ emmc_therm;

    gpio3_adc_default: gpio3_adc_default {
		pins = "gpio3";
		function = "normal";
		bias-high-impedance;
	};

	gpio4_adc_default: gpio4_adc_default {
		pins = "gpio4";
		function = "normal";
		bias-high-impedance;
	};
};

&sec_ap_thermistor {
	use_iio_processed;
	pinctrl-names = "default";
	pinctrl-0 = <&gpio3_adc_default>;

	adc_array = <109191 129822 162975 183412 205211 264251 301686 364165 373248
				452141 573269 669939 740333 805925 924978 1079455 1197015 1305882
				1400086
				1494744 1570004 1637413 1690873>;

	temp_array = <900 850 800 750 700 650 600 550 500
				450 400 350 300 250 200 150 100 50
				0
				(-50) (-100) (-150) (-200)>;
};

&sec_pa_thermistor {
	use_iio_processed;

	adc_array = <113473 134429 165895 189576 216760 266262 304995 366760 411267
				477768 576384 676751 768750 845955 958131 1087045 1205384 1311461
				1407807
				1502270 1576167 1641111 1695350>;

	temp_array = <900 850 800 750 700 650 600 550 500
				450 400 350 300 250 200 150 100 50
				0
				(-50) (-100) (-150) (-200)>;
};

&sec_wf_thermistor {
	use_iio_processed;
	pinctrl-names = "default";
	pinctrl-0 = <&gpio4_adc_default>;

	adc_array = <119961 141435 171020 197361 228179 271518 311029 372599 436959
				500605 586375 685510 788538 879173 986678 1100929 1216608 1320674
				1417668
				1510640 1582720 1646301 1700281>;

	temp_array = <900 850 800 750 700 650 600 550 500
				450 400 350 300 250 200 150 100 50
				0
				(-50) (-100) (-150) (-200)>;
};

/* #include "../../nfc_lsi.dtsi" */                  /* From nfc_lsi.py */
/*
 * This program is free software; you can redistribute it and/or modify
 * it under the terms of the GNU General Public License version 2 and
 * only version 2 as published by the Free Software Foundation.
 *
 * This program is distributed in the hope that it will be useful,
 * but WITHOUT ANY WARRANTY; without even the implied warranty of
 * MERCHANTABILITY or FITNESS FOR A PARTICULAR PURPOSE.  See the
 * GNU General Public License for more details.
 */


&tlmm {
	nfc_i2c_scl_sleep: nfc_i2c_scl_sleep {
		GPIO_CONFIG_PUD_DRV(AP,tlmm,7, FUNC_INPUT, PULL_NONE, DRV_LV3);
	};
	nfc_i2c_sda_sleep: nfc_i2c_sda_sleep {
		GPIO_CONFIG_PUD_DRV(AP,tlmm,6, FUNC_INPUT, PULL_NONE, DRV_LV3);
	};
	nfc_clk_req_gpio: nfc_clk_req_gpio {
		GPIO_CONFIG_PUD_DRV(AP,tlmm,71, FUNC_INPUT, PULL_DOWN, DRV_LV3);
	};
	nfc_irq_gpio: nfc_irq_gpio {
		GPIO_CONFIG_PUD_DRV(AP,tlmm,70, FUNC_INPUT, PULL_DOWN, DRV_LV3);
	};
	nfc_ven_gpio: nfc_ven_gpio {
		GPIO_CONFIG_PUD_DRV(AP,tlmm,69, FUNC_OUTPUT_HIGH, PULL_NONE, DRV_LV3);
	};
	nfc_firm_gpio: nfc_firm_gpio {
		GPIO_CONFIG_PUD_DRV(EXP,gpio_expander,9, FUNC_OUTPUT_LOW, PULL_NONE, DRV_LV3);
	};
};
&tlmm {
	nfc_check_default: nfc_check_default {
		GPIO_CONFIG_PUD_DRV(AP,tlmm,82, FUNC_INPUT, PULL_NONE, DRV_LV3);
	};
};

&qupv3_se2_i2c {
	status = "okay";
	pinctrl-1 = <&nfc_i2c_scl_sleep &nfc_i2c_sda_sleep>;
	sec-nfc@27 {
		compatible = "sec-nfc";
		reg = <0x27>;
		interrupt-parent = <SEC_GPIO_TYPE(AP,tlmm,70)>;
		interrupts = <SEC_GPIO_NUM(AP,tlmm,70) 0>;

		sec-nfc,irq-gpio = <SEC_GPIO_REF(AP,tlmm,70) 0>;
		sec-nfc,ven-gpio = <SEC_GPIO_REF(AP,tlmm,69) 0>;
		sec-nfc,firm-gpio = <SEC_GPIO_REF(EXP,gpio_expander,9) 0>;
		sec-nfc,clk_req-gpio = <SEC_GPIO_REF(AP,tlmm,71) 0>;
		sec-nfc,check_nfc = <SEC_GPIO_REF(AP,tlmm,82) 0>;
		sec-nfc,clk_req_wake;
		sec-nfc,ldo_control;
		nfc_pvdd-supply = <&fixed_regulator4>;
		sec-nfc,bootloader_ver = <6>;

		pinctrl-names = "default";
		pinctrl-0 = <&nfc_clk_req_gpio &nfc_irq_gpio &nfc_ven_gpio &nfc_firm_gpio &nfc_check_default>;
	};
};

/* /home/dpi/qb5_8815/workspace/P4_1716/android/kernel/kmodule/nfc/lsi/nfc_lsi_qc.a23.dtsi */
&qupv3_se2_i2c {
	sec-nfc@27 {
		pinctrl-0 = <&nfc_clk_req_gpio &nfc_irq_gpio &nfc_ven_gpio &nfc_check_default>;
	};
};

/* #include "../../panel_common.dtsi" */             /* From panel_common.py */
/* Dummy for Panel Common */


/* /home/dpi/qb5_8815/workspace/P4_1716/android/kernel/kmodule/display/qc_S/common/panel_common.a23.00.dtsi */
/* override display-list / supply for samsung panel */

&soc {
	ss_dsi_panel_NT36672C_PM6585JB3_FHD_display: qcom,dsi-display@1 {
	       label = "ss_dsi_panel_NT36672C_PM6585JB3_FHD";
	};

	A23_ILI7807S_BS066FBM_display: qcom,dsi-display@2 {
	       label = "A23_ILI7807S_BS066FBM";
	};

	A23_NT36672C_TCFJ6606_display: qcom,dsi-display@3 {
	       label = "A23_NT36672C_TCFJ6606";
	};

	A23_FT8720_LPS066A767A_display: qcom,dsi-display@4 {
	       label = "A23_FT8720_LPS066A767A";
	};

	/* PBA */
	ss_dsi_panel_PBA_BOOTING_FHD_display: qcom,dsi-display@0 {
		label = "ss_dsi_panel_PBA_BOOTING_FHD";
	};
};

/* #include "../../s2mu106_charger.dtsi" */          /* From s2mu106_charger.py */
&smd {
	s2mu106_charger: s2mu106-charger {
		status = "disable";
		compatible = "samsung,s2mu106-charger";
	};

	battery {
		battery,otg_name = "s2mu106-otg";
	};
};


/* #include "../../sec_direct_charger.dtsi" */       /* From sec_direct_charger.py */

&smd {
	sec-direct-charger {
		status = "okay";
		compatible = "samsung,sec-direct-charger";

		charger,battery_name = "battery";
		charger,main_charger = "s2mu106-charger";
		charger,direct_charger = "hl7132-charger";

		charger,dchg_min_current = <2000>;

		charger,ta_alert_wa;
	};
};


/* /home/dpi/qb5_8815/workspace/P4_1716/android/kernel/kmodule/battery/suwon/common/sec_direct_charger/dts/a23/sec_direct_charger.dtsi */

&smd {
	pass-through {
		start_delay = <5000>; /* msec */
		init_delay = <5000>; /* msec */
		min_cap = <200>; /* 0.1 % */
		fixed_sc_cap = <900>; /* 0.1 % */
		max_icl = <3000>; /* mA */
		vfloat = <4380>; /* mV */
	};
};


/* #include "../../battery_common.dtsi" */           /* From battery_common.py */
#include <dt-bindings/battery/sec-battery.h>

&smd {
	sec_battery: battery {
		status = "okay";
		compatible = "samsung,sec-battery";
		battery,vendor = "Battery";
		battery,charger_name = "sec-direct-charger";
		battery,fuelgauge_name = "s2mu106-fuelgauge";
		battery,technology = <2>; /* POWER_SUPPLY_TECHNOLOGY_LION */
		battery,chip_vendor = "NONE";

		battery,batt_data_version = <1>;

		battery,adc_check_count = <5>;
		battery,temp_check_type = <SEC_BATTERY_TEMP_CHECK_NONE>;
		battery,usb_temp_check_type = <SEC_BATTERY_TEMP_CHECK_NONE>;
		battery,chg_temp_check_type = <SEC_BATTERY_TEMP_CHECK_NONE>;
		battery,wpc_temp_check_type = <SEC_BATTERY_TEMP_CHECK_NONE>;
		battery,lrp_temp_check_type = <SEC_BATTERY_TEMP_CHECK_NONE>;

		battery,thermal_source = <SEC_BATTERY_THERMAL_SOURCE_NONE>; /* SEC_BATTERY_THERMAL_SOURCE_NONE */
		battery,usb_thermal_source = <SEC_BATTERY_THERMAL_SOURCE_NONE>; /* SEC_BATTERY_THERMAL_SOURCE_NONE */
		battery,chg_thermal_source = <SEC_BATTERY_THERMAL_SOURCE_NONE>; /* SEC_BATTERY_THERMAL_SOURCE_NONE */
		battery,wpc_thermal_source = <SEC_BATTERY_THERMAL_SOURCE_NONE>; /* SEC_BATTERY_THERMAL_SOURCE_NONE */

		battery,inbat_ocv_type =  <SEC_BATTERY_OCV_NONE>;

		battery,polling_time = <10 30 30 30 3600>;

		battery,cable_check_type = <SEC_BATTERY_CABLE_CHECK_PSY>;
		battery,cable_source_type = <SEC_BATTERY_CABLE_SOURCE_EXTERNAL>;
		battery,polling_type = <SEC_BATTERY_MONITOR_ALARM>; /* SEC_BATTERY_MONITOR_ALARM */
		battery,monitor_initial_count = <0>;

		battery,battery_check_type = <0>; /* SEC_BATTERY_CHECK_NONE */

		battery,ovp_uvlo_check_type = <SEC_BATTERY_OVP_UVLO_CHGPOLLING>; /* SEC_BATTERY_OVP_UVLO_CHGPOLLING */

		battery,temp_check_count = <1>;

		battery,usb_protection_temp = <610>;
		battery,temp_gap_bat_usb = <200>;
		battery,overheatlimit_threshold = <700>;
		battery,overheatlimit_recovery = <680>;
		battery,wire_warm_overheat_thresh = <500>;
		battery,wire_normal_warm_thresh = <420>;
		battery,wire_cool1_normal_thresh = <180>;
		battery,wire_cool2_cool1_thresh = <150>;
		battery,wire_cool3_cool2_thresh = <50>;
		battery,wire_cold_cool3_thresh = <0>;
		battery,wireless_warm_overheat_thresh = <500>;
		battery,wireless_normal_warm_thresh = <420>;
		battery,wireless_cool1_normal_thresh = <180>;
		battery,wireless_cool2_cool1_thresh = <150>;
		battery,wireless_cool3_cool2_thresh = <50>;
		battery,wireless_cold_cool3_thresh = <0>;
		battery,tx_high_threshold = <500>;
		battery,tx_high_recovery = <450>;
		battery,tx_low_threshold = <0>;
		battery,tx_low_recovery = <50>;

		battery,wire_warm_current = <1573>;	/* 0.36C */
		battery,wire_cool1_current = <3146>;	/* 0.72C */
		battery,wire_cool2_current = <1048>;	/* 0.24C */
		battery,wire_cool3_current = <437>;	/* 0.1C */
		battery,wireless_warm_current = <1048>;		/* 0.24C */
		battery,wireless_cool1_current = <3146>;	/* 0.72C */
		battery,wireless_cool2_current = <1048>;	/* 0.24C */
		battery,wireless_cool3_current = <437>;		/* 0.1C */

		battery,full_check_type = <SEC_BATTERY_FULLCHARGED_CHGPSY>;
		battery,full_check_type_2nd = <SEC_BATTERY_FULLCHARGED_CHGPSY>;
		battery,full_check_count = <1>;
		battery,chg_gpio_full_check = <0>;
		battery,chg_polarity_full_check = <1>;

		battery,chg_high_temp = <470>;
		battery,chg_high_temp_recovery = <450>;
		battery,chg_input_limit_current = <1000>;
		battery,chg_charging_limit_current = <1900>;

		battery,dchg_high_temp = <520>;
		battery,dchg_high_temp_recovery = <460>;
		battery,dchg_high_batt_temp = <400>;
		battery,dchg_high_batt_temp_recovery = <380>;
		battery,dchg_input_limit_current = <1000>;
		battery,dchg_charging_limit_current = <2000>;

		battery,wpc_temp_control_source = <TEMP_CONTROL_SOURCE_BAT_THM>;
		battery,wpc_high_temp = <400>;
		battery,wpc_high_temp_recovery = <380>;
		battery,wpc_input_limit_current = <800>;
		battery,wpc_charging_limit_current = <1000>;
		battery,wpc_temp_lcd_on_control_source = <TEMP_CONTROL_SOURCE_BAT_THM>;
		battery,wpc_lcd_on_input_limit_current = <800>;

		battery,wpc_store_high_temp = <360>;
		battery,wpc_store_high_temp_recovery = <340>;
		battery,wpc_store_charging_limit_current = <400>;
		battery,wpc_store_lcd_on_high_temp = <360>;
		battery,wpc_store_lcd_on_high_temp_rec = <300>;
		battery,wpc_store_lcd_on_charging_limit_current = <400>;

		battery,fcc_by_tx = <1200>;

		battery,sleep_mode_limit_current = <800>;
		battery,wc_full_input_limit_current = <100>;

		battery,ta_alert_wa;

		battery,mix_high_temp = <420>;
		battery,mix_high_chg_temp = <500>;
		battery,mix_high_temp_recovery = <390>;

		/* battery,usb_conn_slope_avg = <9>; */

		/* battery,enable_mix_v2; */
		/* if you want to use mix_v2 concept, add "battery,enable_mix_v2;" */
		battery,mix_v2_lrp_recov = <460>;
		battery,mix_v2_lrp_cond = <480>;
		battery,mix_v2_bat_cond = <480>;
		battery,mix_v2_chg_cond = <0>;	/* 0 means no use chg thm condition */
		battery,mix_v2_dchg_cond = <0>; /* 0 means no use dchg thm condition */

		battery,full_condition_type = <(SEC_BATTERY_FULL_CONDITION_NOTIMEFULL | SEC_BATTERY_FULL_CONDITION_VCELL)>;
		battery,full_condition_soc = <93>;
		/* battery,full_condition_vcell = FV - 50mV set when variable is parsed */

		battery,recharge_check_count = <1>;
		battery,recharge_condition_type = <SEC_BATTERY_RECHARGE_CONDITION_VCELL>;
		battery,recharge_condition_soc = <98>;
		/* battery,recharge_condition_vcell = FV - 70mV set when variable is parsed */

		battery,charging_reset_time = <0>;

		battery,chg_float_voltage = <4350>;

		battery,pre_afc_work_delay = <2000>;
		battery,pre_wc_afc_work_delay = <4000>;
		battery,pre_afc_input_current = <500>;
		battery,pre_wc_afc_input_current = <500>;

		battery,swelling_high_rechg_voltage = <4000>;
		/*battery,swelling_low_rechg_voltage = FV - 150mA set when variable is parsed */

		battery,siop_icl = <1200>;
		battery,siop_fcc = <1800>;
		battery,siop_hv_icl = <700>;
		battery,siop_hv_icl_2nd = <550>;
		battery,siop_hv_fcc = <1800>;
		battery,siop_apdo_icl = <1000>;
		battery,siop_apdo_fcc = <2000>;

		battery,siop_wpc_icl = <600>;
		battery,siop_wpc_fcc = <1000 500 100>; /* siop_level 70 10 0 */
		battery,siop_hv_wpc_icl = <700>;
		battery,siop_hv_wpc_fcc = <1000 500 100>; /* siop_level 70 10 0 */
		battery,siop_store_hv_wpc_icl = <450>;
		battery,store_mode_buckoff;

		/* trig, recov */
		battery,temp_table_LRP_45W = <385 365>;

		battery,rp_current_rp1 = <500>;
		battery,rp_current_rp2 = <1500>;
		battery,rp_current_rp3 = <3000>;
		battery,rp_current_rdu_rp3 = <2100>;
		battery,rp_current_abnormal_rp3 = <1800>;

		battery,pd_charging_charge_power = <15000>;
		battery,max_charging_current = <2350>;

		battery,store_mode_charging_max = <70>;
		battery,store_mode_charging_min = <60>;

		battery,wireless_cc_cv = <85>;
		battery,wireless_otg_input_current = <900>;

		/* Calculate Based on Offsets from float voltage, full_condition_vcell and recharge_condition_vcell */
		/* if you want to use age_data_by_common_offset concept add battery,age_data_by_common_offset; */

		battery,age_data_cycle = <0 300 400 700 1000>;
		battery,age_data_full_condition_soc = <93 92 91 90 89>;
		battery,age_data_common_offset = <0 20 40 110>;
		/* battery,age_data_max_charging_current_offset = <0 100 200 300 400>; */

		/* cycle, chg_float_voltage, recharge_condition_vcell, full_condition_vcell, full_condition_soc, step charging condition */
		battery,age_data = <0 4350 4280 4250 93
			300 4330 4260 4230 92
			400 4310 4240 4210 91
			700 4290 4220 4190 90
			1000 4240 4170 4140 89>;


		battery,health_condition_cycle = <900 1200 1500>;
		battery,health_condition_asoc = <0 0 0>; /* Default ASOC Disabled */

		battery,max_input_voltage = <9000>; /* mV */
		battery,max_input_current = <3000>;  /* mA */

		battery,cisd_alg_index = <8>;
		battery,cisd_max_voltage_thr = <4400>; /* batttery ovp dettection voltage */
		battery,ignore_cisd_index = <0 0>;
		battery,ignore_cisd_index_d = <0 80>; /* Do not use BUCK_OFF_PER_DAY, DROP_SENSOR_PER_DAY */

		battery,expired_time = <10800>;
		battery,recharging_expired_time = <5400>;

		battery,battery_full_capacity = <3300>;

		battery,ttf_capacity = <3500>;
		battery,cv_data = <
				3228	864	1534
				3133	866	1524
				3067	872	1493
				3019	874	1483
				2929	879	1452
				2896	881	1442
				2843	883	1431
				2792	885	1421
				2754	887	1411
				2695	892	1380
				2660	893	1370
				2625	895	1360
				2580	897	1349
				2531	898	1339
				2492	902	1319
				2450	903	1309
				2410	905	1298
				2348	908	1278
				2296	909	1268
				2263	910	1257
				2214	915	1227
				2182	916	1216
				2147	919	1196
				2103	920	1186
				2051	922	1175
				2019	924	1155
				1981	927	1134
				1948	928	1124
				1911	930	1104
				1879	932	1093
				1834	933	1083
				1795	935	1063
				1761	938	1032
				1722	942	1001
				1689	944	981
				1649	946	960
				1592	948	940
				1532	950	919
				1493	954	878
				1462	955	868
				1410	958	827
				1362	959	817
				1338	960	807
				1291	964	756
				1264	968	715
				1237	968	704
				1213	969	694
				1169	974	633
				1127	975	622
				1105	975	612
				1073	980	541
				1049	982	510
				1010	983	489
				993	984	479
				972	986	448
				955	988	407
				932	990	387
				881	990	377
				864	996	356
				761	1000	307
				710	1000	297
				688	1000	287
				668	1000	235
				658	1000	215
				647	1000	184
				635	1000	153
				622	1000	123
				610	1000	92
				596	1000	61
				583	1000	31
				571	1000	0
				>;

		io-channels = <&pm6125_vadc 0x4E>;
		io-channel-names = "adc-temp", "n/a", "n/a", "n/a", "n/a";
	};

	/* sec_battery_cable
	 *   0	UNKNOWN,
	 *   1	NONE,
	 *   2	PREPARE_TA,
	 *   3	TA,
	 *   4	USB,
	 *   5	USB_CDP,
	 *   6	9V_TA,
	 *   7	9V_ERR,
	 *   8	9V_UNKNOWN,
	 *   9	12V_TA,
	 *  10	WIRELESS,
	 *  11	HV_WIRELESS,
	 *  12	PMA_WIRELESS,
	 *  13	WIRELESS_PACK,
	 *  14	CABLE_WIRELESS_HV_PACK,
	 *  15	WIRELESS_STAND,
	 *  16	WIRELESS_HV_STAND,
	 *  17	QC20,
	 *  18	QC30,
	 *  19	PDIC,
	 *  20	UARTOFF,
	 *  21	OTG,
	 *  22	LAN_HUB,
	 *  23	POWER_SHARING,
	 *  24	HMT_CONNECTED,
	 *  25	HMT_CHARGE,
	 *  26	HV_TA_CHG_LIMIT,
	 *  27	WIRELESS_VEHICLE,
	 *  28	WIRELESS_HV_VEHICLE,
	 *  29	PREPARE_WIRELESS_HV,
	 *  30  TIMEOUT,
	 *  31  SMART_OTG,
	 *  32  SMART_NOTG,
	 *  33  WIRELESS_TX,
	 *  34	HV_WIRELESS_20,
	 *  35	HV_WIRELESS_20_LIMIT,
	 *  36	WIRELESS_FAKE,
	 *  37  PREPARE_WIRELESS_20,
	 *  38	CABLE_PDIC_APDO,
	 *  39  CABLE_POGO,
	 *  40  CABLE_POGO_9V,
	 *  41  FPDO_DC,
	 *  42	CABLE_MAX,
	 */
	sec_battery_cable: cable-info {
		default_input_current = <1800>;
		default_charging_current = <2100>;
		full_check_current_1st = <350>;
		full_check_current_2nd = <200>;

		current_group_1 {
			cable_number = <
				SEC_BATTERY_CABLE_PREPARE_TA
				SEC_BATTERY_CABLE_PDIC
				SEC_BATTERY_CABLE_OTG
				SEC_BATTERY_CABLE_LAN_HUB
				SEC_BATTERY_CABLE_POWER_SHARING>;
			input_current = <500>;
			charging_current = <500>;
		};
		current_group_2 {
			cable_number = <
				SEC_BATTERY_CABLE_HMT_CHARGE
				SEC_BATTERY_CABLE_SMART_OTG>;
			input_current = <1000>;
			charging_current = <1000>;
		};
		current_group_3 {
			cable_number = <
				SEC_BATTERY_CABLE_USB_CDP
				SEC_BATTERY_CABLE_SMART_NOTG>;
			input_current = <1500>;
			charging_current = <1500>;
		};
		current_group_4 {
			cable_number = <SEC_BATTERY_CABLE_9V_TA SEC_BATTERY_CABLE_9V_ERR
				SEC_BATTERY_CABLE_9V_UNKNOWN SEC_BATTERY_CABLE_QC20 SEC_BATTERY_CABLE_QC30>;
			input_current = <1650>;
			charging_current = <2350>;
		};
		current_group_5 {
			cable_number = <SEC_BATTERY_CABLE_12V_TA>;
			input_current = <1650>;
			charging_current = <2350>;
		};
		current_group_6 {
			cable_number = <
				SEC_BATTERY_CABLE_WIRELESS
				SEC_BATTERY_CABLE_PMA_WIRELESS
				SEC_BATTERY_CABLE_WIRELESS_STAND
				SEC_BATTERY_CABLE_WIRELESS_VEHICLE
				SEC_BATTERY_CABLE_WIRELESS_FAKE>;
			input_current = <800>;
			charging_current = <2350>;
		};
		current_group_7 {
			cable_number = <SEC_BATTERY_CABLE_WIRELESS_PACK>;
			input_current = <700>;
			charging_current = <2350>;
		};
		current_group_8 {
			cable_number = <SEC_BATTERY_CABLE_HMT_CONNECTED>;
			input_current = <1000>;
			charging_current = <450>;
		};
		current_group_9 {
			cable_number = <SEC_BATTERY_CABLE_HV_TA_CHG_LIMIT>;
			input_current = <1800>;
			charging_current = <1800>;
		};
		current_group_10 {
			cable_number = <
				SEC_BATTERY_CABLE_HV_WIRELESS
				SEC_BATTERY_CABLE_WIRELESS_HV_PACK
				SEC_BATTERY_CABLE_WIRELESS_HV_STAND
				SEC_BATTERY_CABLE_WIRELESS_HV_VEHICLE
				SEC_BATTERY_CABLE_HV_WIRELESS_20_LIMIT>;
			input_current = <650>;
			charging_current = <2350>;
		};
		current_group_11 {
			cable_number = <
				SEC_BATTERY_CABLE_PREPARE_WIRELESS_HV
				SEC_BATTERY_CABLE_PREPARE_WIRELESS_20>;
			input_current = <500>;
			charging_current = <1200>;
		};
		current_group_12 {
			cable_number = <
				SEC_BATTERY_CABLE_NONE
				SEC_BATTERY_CABLE_USB
				SEC_BATTERY_CABLE_TIMEOUT>;
			input_current = <475>;
			charging_current = <550>;
		};
		current_group_13 {
			cable_number = <SEC_BATTERY_CABLE_HV_WIRELESS_20>;
			input_current = <1200>;
			charging_current = <2350>;
		};
		current_group_14 {
			cable_number = <SEC_BATTERY_CABLE_WIRELESS_TX>;
			input_current = <800>;
			charging_current = <2350>;
		};
	};
	sec_battery_wireless_power_info: wireless-power-info {
		count = <9>;
		current_group_0 {
			wireless_power_class = <2>;
			vout = <9000>;
			input_current_limit = <830>;
			fast_charging_current = <3150>;
			ttf_charge_current = <1500>;
			rx_power = <7500>;
		};
		current_group_1 {
			wireless_power_class = <2>;
			vout = <10000>;
			input_current_limit = <750>;
			fast_charging_current = <3150>;
			ttf_charge_current = <1500>;
			rx_power = <7500>;
		};
		current_group_2 {
			wireless_power_class = <2>;
			vout = <11000>;
			input_current_limit = <680>;
			fast_charging_current = <3150>;
			ttf_charge_current = <1500>;
			rx_power = <7500>;
		};
		current_group_3 {
			wireless_power_class = <2>;
			vout = <12000>;
			input_current_limit = <625>;
			fast_charging_current = <3150>;
			ttf_charge_current = <1500>;
			rx_power = <7500>;
		};
		current_group_4 {
			wireless_power_class = <2>;
			vout = <9000>;
			input_current_limit = <1330>;
			fast_charging_current = <3150>;
			ttf_charge_current = <2175>;
			rx_power = <12000>;
		};
		current_group_5 {
			wireless_power_class = <2>;
			vout = <11000>;
			input_current_limit = <1090>;
			fast_charging_current = <3150>;
			ttf_charge_current = <2100>;
			rx_power = <12000>;
		};
		current_group_6 {
			wireless_power_class = <2>;
			vout = <12000>;
			input_current_limit = <1000>;
			fast_charging_current = <3150>;
			ttf_charge_current = <2100>;
			rx_power = <12000>;
		};
		current_group_7 {
			wireless_power_class = <2>;
			vout = <11000>;
			input_current_limit = <1360>;
			fast_charging_current = <3150>;
			ttf_charge_current = <2300>;
			rx_power = <15000>;
		};
		current_group_8 {
			wireless_power_class = <2>;
			vout = <12000>;
			input_current_limit = <1250>;
			fast_charging_current = <3150>;
			ttf_charge_current = <2300>;
			rx_power = <15000>;
		};
	};
};

/* /home/dpi/qb5_8815/workspace/P4_1716/android/kernel/kmodule/battery/suwon/common/dts/a23/battery_common.dtsi */

&pm6125_vadc {
	bat_thm { /* AMUX_2 */
		label = "bat_thm";
		reg = <ADC5_AMUX_THM2_100K_PU>;
		qcom,pre-scaling = <1 1>;
		qcom,hw-settle-time = <200>;
		qcom,ratiometric;
		qcom,scale-fn-type = <ADC_SCALE_HW_CALIB_DEFAULT>;
	};
};

&sec_battery {
		pinctrl-names = "default";

		battery,batt_data_version = <1>;
		battery,chip_vendor = "SM";

		battery,temp_check_type = <SEC_BATTERY_TEMP_CHECK_TEMP>;
		battery,chg_temp_check_type = <SEC_BATTERY_TEMP_CHECK_TEMP>;
		battery,dchg_temp_check_type = <SEC_BATTERY_TEMP_CHECK_TEMP>;

		battery,thermal_source = <SEC_BATTERY_THERMAL_SOURCE_ADC>;
		battery,chg_thermal_source = <SEC_BATTERY_THERMAL_SOURCE_FG>;
		battery,dchg_thermal_source = <SEC_BATTERY_THERMAL_SOURCE_CHG_ADC>;

		battery,temp_table_adc = <131173 153471 179281 210899 246864
				289251 337824 397945 500090 578740
				627097 721950 824458 930341 1040181
				1151167 1256574 1357136 1449329 1532504
				1602638 1662564 1716435>;
		battery,temp_table_data = <900 850 800 750 700 650 600 550 500 450
				400 350 300 250 200 150 100 50 0 (-50) (-100) (-150) (-200)>;

		battery,dchg_temp_table_adc = <117920 140800 168960 197120 235840
				278080 329120 383680 443520 517440
				600160 707520 811360 915200 1022560
				1126400 1224960 1320000 1388640 1467840
				1536480 1598080 1650880>;
		battery,dchg_temp_table_data = <900 850 800 750 700 650 600 550 500 450
				400 350 300 250 200 150 100 50 0 (-50) (-100) (-150) (-200)>;

		battery,temp_check_count = <1>;
		battery,wire_warm_overheat_thresh = <500>;
		battery,wire_normal_warm_thresh = <420>;
		battery,wire_cool1_normal_thresh = <180>;
		battery,wire_cool2_cool1_thresh = <150>;
		battery,wire_cool3_cool2_thresh = <50>;
		battery,wire_cold_cool3_thresh = <0>;

		battery,wire_warm_current = <1700>;	/* 0.36C */
		battery,wire_cool1_current = <2800>;	/* 0.72C */
		battery,wire_cool2_current = <1150>;	/* 0.24C */
		battery,wire_cool3_current = <450>;	/* 0.1C */

		battery,high_temp_topoff = <250>;
		battery,low_temp_topoff = <250>;
		battery,high_temp_float = <4150>;
		battery,low_temp_float = <4380>;
		battery,swelling_high_rechg_voltage = <4000>;
		battery,swelling_low_rechg_voltage = <4230>;

		battery,chg_high_temp = <560>;
		battery,chg_high_temp_recovery = <540>;

		battery,dchg_high_temp = <650>;
		battery,dchg_high_temp_recovery = <630>;

		battery,full_check_type = <SEC_BATTERY_FULLCHARGED_FG_CURRENT>;
		battery,full_check_type_2nd = <SEC_BATTERY_FULLCHARGED_FG_CURRENT>;

		battery,full_condition_vcell = <4370>;
		battery,recharge_condition_vcell = <4310>;
		battery,chg_float_voltage = <4380>;
		battery,chg_ocp_current = <9000>;

		battery,siop_event_check_type = <1>;
		battery,siop_call_cv_current = <330>;
		battery,siop_call_cc_current = <330>;

		battery,siop_apdo_input_limit_current = <1200>;
		battery,siop_apdo_charging_limit_current = <2000>;

		battery,ttf_hv_charge_current = <2430>;
		battery,ttf_dc25_charge_current = <3450>;

		battery,mix_high_temp = <460>;
		battery,mix_high_chg_temp = <500>;
		battery,mix_high_temp_recovery = <430>;

		battery,max_charging_current = <2800>;
		battery,max_charging_charge_power = <25000>; /* 25W */

		/* cycle, chg_float_voltage, recharge_condition_vcell, full_condition_vcell, full_condition_soc, step charging condition */
		battery,age_data = <0 4380 4310 4330 93
				300 4360 4290 4310 92
				400 4340 4270 4290 91
				700 4320 4250 4270 90
				1000 4270 4200 4220 89>;

		/* direct step charging option */
		battery,dc_step_chg_type = <0xE9>;
		battery,dc_step_chg_charge_power = <22000>;
		battery,dc_step_chg_step = <3>;
		battery,dc_step_chg_cond_v_margin = <40>; /* mV */
		battery,dc_step_chg_cond_vol = <4000 4180 4380>; /* STEP_CHARGING_CONDITION_VOLTAGE */
		battery,dc_step_chg_cond_iin = <1900 1725 0>; /* STEP_CHARGING_CONDITION_INPUT_CURRENT */
		battery,dc_step_chg_iin_check_cnt = <3>;
		battery,dc_step_chg_cond_soc = <33 70 100>; /* STEP_CHARGING_CONDITION_SOC */
		battery,dc_step_chg_val_vfloat = <4000 4180 4380>; /* STEP_CHARGING_CONDITION_FLOAT_VOLTAGE */
		battery,dc_step_chg_val_iout = <4000 3800 3450>;

		battery,enable_sysovlo_irq;
		battery,enable_noise_wa;

		battery,standard_curr = <3450>;
		battery,expired_time = <9120>; /* 92 + 60 minutes = 152 */
		battery,recharging_expired_time = <5400>; /* 90 minutes */
		battery,battery_full_capacity = <4500>;
		battery,cisd_max_voltage_thr = <5000>; /* batttery ovp dettection voltage */

		battery,ttf_capacity = <4180>;
		battery,cv_data = <
					3365	616	2220
					3349	628	2160
					3293	640	2100
					3335	653	2040
					3291	665	1980
					3334	677	1920
					3306	690	1860
					3248	702	1800
					3296	715	1740
					3330	727	1680
					3309	739	1620
					3175	751	1560
					3260	763	1500
					3292	776	1440
					3261	788	1380
					3253	800	1320
					3274	812	1260
					3029	824	1200
					2840	835	1140
					2677	845	1080
					2524	854	1020
					2256	863	960
					2113	871	900
					1956	879	840
					1898	886	780
					1788	893	720
					1641	899	660
					1507	905	600
					1481	915	540
					1350	925	480
					1194	935	420
					1177	945	360
					1066	955	300
					1048	965	240
					1012	975	180
					750	985	120
					729	995	60
					688	1000	0
					>;
};

&sec_battery_cable {
		full_check_current_1st = <750>;
		full_check_current_2nd = <250>;

		current_group_1 {
			cable_number = <
				SEC_BATTERY_CABLE_PDIC
				SEC_BATTERY_CABLE_OTG
				SEC_BATTERY_CABLE_LAN_HUB
				SEC_BATTERY_CABLE_POWER_SHARING>;
			input_current = <500>;
			charging_current = <500>;
		};

		current_group_4 {
			charging_current = <2800>;
		};
		current_group_5 {
			charging_current = <2800>;
		};
};

/* revision devicetree for general */
#include "khaje-sec.a23.01.dtsi"

/* common devicetree for general */
#include "khaje-sec.a23_eur_open.dtsi"

/ {
	compatible = "qcom,khaje-idp","qcom,khaje:qcom,idp";
	dtbo-hw_rev = <1>;
	dtbo-hw_rev_end = <32>;
};
